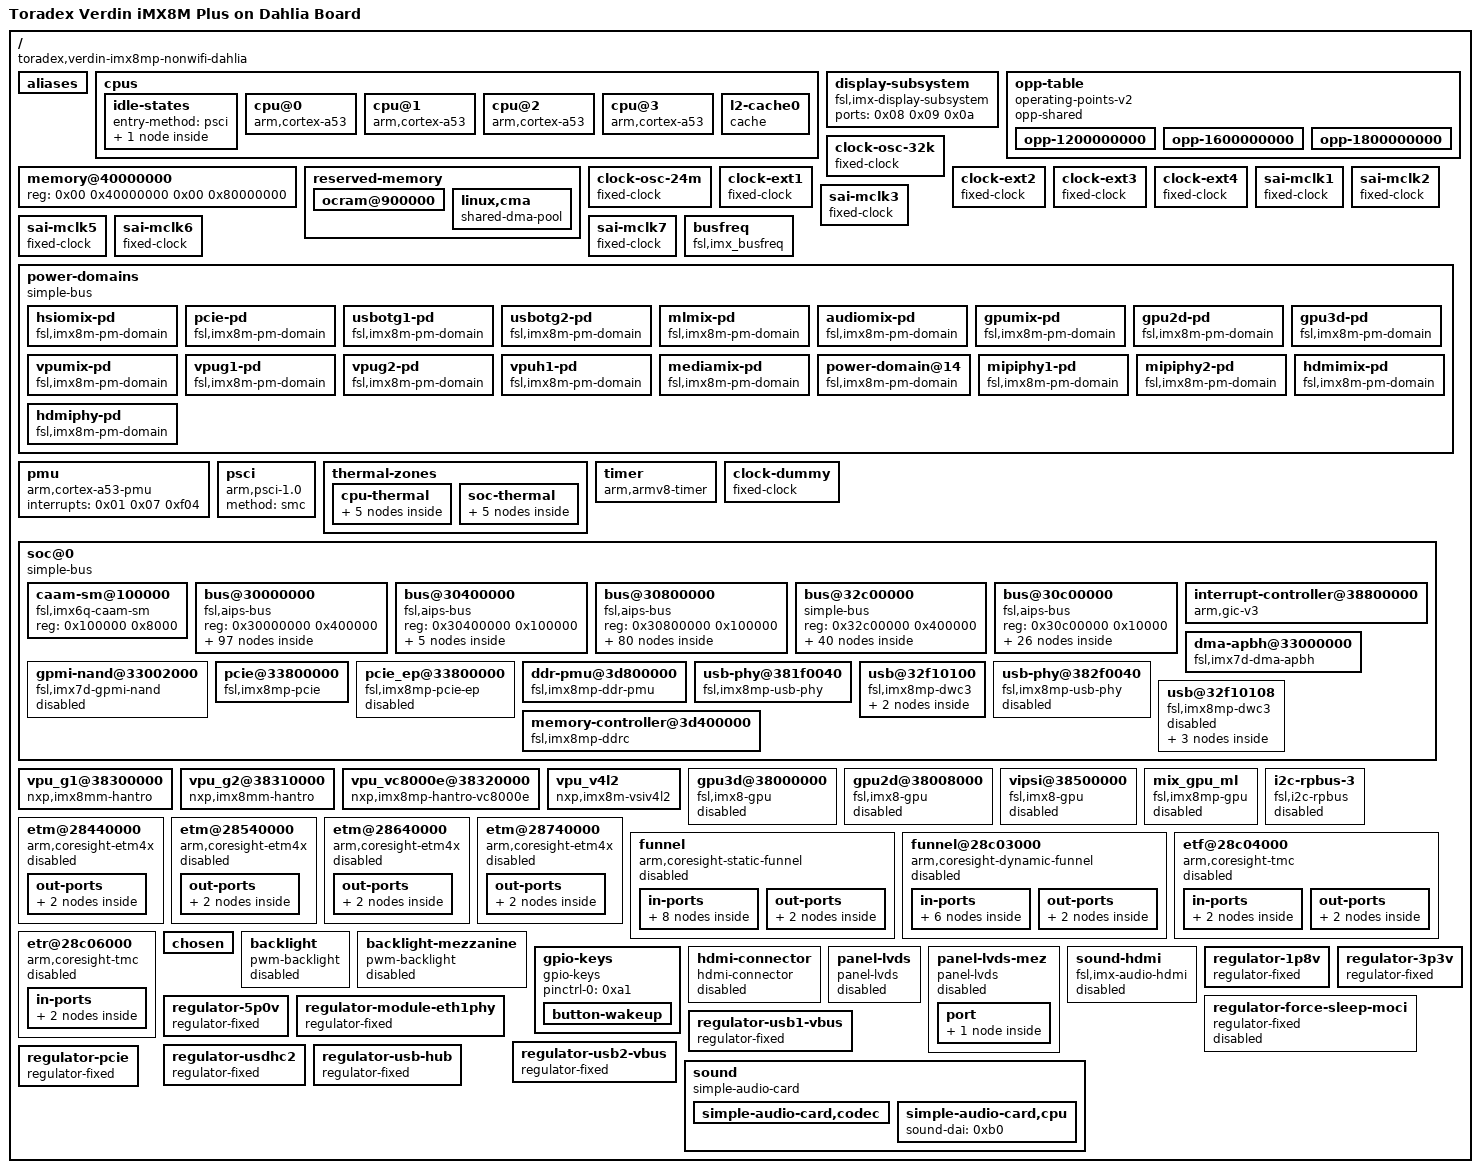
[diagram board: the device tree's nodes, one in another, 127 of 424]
/dts-v1/;

/ {
	interrupt-parent = <0x01>;
	#address-cells = <0x02>;
	#size-cells = <0x02>;
	model = "Toradex Verdin iMX8M Plus on Dahlia Board";
	compatible = "toradex,verdin-imx8mp-nonwifi-dahlia", "toradex,verdin-imx8mp-nonwifi", "toradex,verdin-imx8mp", "fsl,imx8mp";

	aliases {
		ethernet0 = "/soc@0/bus@30800000/ethernet@30bf0000";
		ethernet1 = "/soc@0/bus@30800000/ethernet@30be0000";
		gpio0 = "/soc@0/bus@30000000/gpio@30200000";
		gpio1 = "/soc@0/bus@30000000/gpio@30210000";
		gpio2 = "/soc@0/bus@30000000/gpio@30220000";
		gpio3 = "/soc@0/bus@30000000/gpio@30230000";
		gpio4 = "/soc@0/bus@30000000/gpio@30240000";			/* This is actually called "GPIO5 base address: 3024_0000h" in the TRM! WTF?? -josh */
		i2c0 = "/soc@0/bus@30800000/i2c@30a20000";
		i2c1 = "/soc@0/bus@30800000/i2c@30a30000";
		i2c2 = "/soc@0/bus@30800000/i2c@30a40000";
		i2c3 = "/soc@0/bus@30800000/i2c@30a50000";
		i2c4 = "/soc@0/bus@30800000/i2c@30ad0000";
		i2c5 = "/soc@0/bus@30800000/i2c@30ae0000";
		mmc0 = "/soc@0/bus@30800000/mmc@30b40000";
		mmc1 = "/soc@0/bus@30800000/mmc@30b50000";
		mmc2 = "/soc@0/bus@30800000/mmc@30b60000";
		serial0 = "/soc@0/bus@30800000/serial@30860000";
		serial1 = "/soc@0/bus@30800000/serial@30890000";
		serial2 = "/soc@0/bus@30800000/serial@30880000";
		serial3 = "/soc@0/bus@30800000/serial@30a60000";
		spi0 = "/soc@0/bus@30800000/spi@30bb0000";
		isi0 = "/soc@0/bus@32c00000/camera/isi@32e00000";
		isi1 = "/soc@0/bus@32c00000/camera/isi@32e02000";
		csi0 = "/soc@0/bus@32c00000/camera/csi@32e40000";
		csi1 = "/soc@0/bus@32c00000/camera/csi@32e50000";
		isp0 = "/soc@0/bus@32c00000/camera/isp@32e10000";
		isp1 = "/soc@0/bus@32c00000/camera/isp@32e20000";
		rtc0 = "/soc@0/bus@30800000/i2c@30a20000/rtc@32";
		rtc1 = "/soc@0/bus@30000000/snvs@30370000/snvs-rtc-lp";
	};

	cpus {
		#address-cells = <0x01>;
		#size-cells = <0x00>;

		idle-states {
			entry-method = "psci";

			cpu-pd-wait {
				compatible = "arm,idle-state";
				arm,psci-suspend-param = <0x10033>;
				local-timer-stop;
				entry-latency-us = <0x3e8>;
				exit-latency-us = <0x2bc>;
				min-residency-us = <0xa8c>;
				wakeup-latency-us = <0x5dc>;
				phandle = <0x06>;
			};
		};

		cpu@0 {
			device_type = "cpu";
			compatible = "arm,cortex-a53";
			reg = <0x00>;
			clock-latency = <0xee6c>;
			clocks = <0x02 0x11f>;
			operating-points-v2 = <0x03>;
			nvmem-cells = <0x04>;
			nvmem-cell-names = "speed_grade";
			enable-method = "psci";
			next-level-cache = <0x05>;
			#cooling-cells = <0x02>;
			cpu-idle-states = <0x06>;
			cpu-supply = <0x07>;
			phandle = <0x12>;
		};

		cpu@1 {
			device_type = "cpu";
			compatible = "arm,cortex-a53";
			reg = <0x01>;
			clock-latency = <0xee6c>;
			clocks = <0x02 0x11f>;
			operating-points-v2 = <0x03>;
			enable-method = "psci";
			next-level-cache = <0x05>;
			#cooling-cells = <0x02>;
			cpu-idle-states = <0x06>;
			cpu-supply = <0x07>;
			phandle = <0x13>;
		};

		cpu@2 {
			device_type = "cpu";
			compatible = "arm,cortex-a53";
			reg = <0x02>;
			clock-latency = <0xee6c>;
			clocks = <0x02 0x11f>;
			operating-points-v2 = <0x03>;
			enable-method = "psci";
			next-level-cache = <0x05>;
			#cooling-cells = <0x02>;
			cpu-idle-states = <0x06>;
			cpu-supply = <0x07>;
			phandle = <0x14>;
		};

		cpu@3 {
			device_type = "cpu";
			compatible = "arm,cortex-a53";
			reg = <0x03>;
			clock-latency = <0xee6c>;
			clocks = <0x02 0x11f>;
			operating-points-v2 = <0x03>;
			enable-method = "psci";
			next-level-cache = <0x05>;
			#cooling-cells = <0x02>;
			cpu-idle-states = <0x06>;
			cpu-supply = <0x07>;
			phandle = <0x15>;
		};

		l2-cache0 {
			compatible = "cache";
			phandle = <0x05>;
		};
	};

	display-subsystem {
		compatible = "fsl,imx-display-subsystem";
		ports = <0x08 0x09 0x0a>;
	};

	opp-table {
		compatible = "operating-points-v2";
		opp-shared;
		phandle = <0x03>;

		opp-1200000000 {
			opp-hz = <0x00 0x47868c00>;
			opp-microvolt = <0xcf850>;
			opp-supported-hw = <0x8a0 0x07>;
			clock-latency-ns = <0x249f0>;
			opp-suspend;
		};

		opp-1600000000 {
			opp-hz = <0x00 0x5f5e1000>;
			opp-microvolt = <0xe7ef0>;
			opp-supported-hw = <0xa0 0x07>;
			clock-latency-ns = <0x249f0>;
			opp-suspend;
		};

		opp-1800000000 {
			opp-hz = <0x00 0x6b49d200>;
			opp-microvolt = <0xf4240>;
			opp-supported-hw = <0x20 0x03>;
			clock-latency-ns = <0x249f0>;
			opp-suspend;
		};
	};

	memory@40000000 {
		device_type = "memory";
		reg = <0x00 0x40000000 0x00 0x80000000>;
	};

	reserved-memory {
		#address-cells = <0x02>;
		#size-cells = <0x02>;
		ranges;
		phandle = <0xb1>;

		ocram@900000 {
			no-map;
			reg = <0x00 0x900000 0x00 0x70000>;
			phandle = <0xb2>;
		};

		linux,cma {
			compatible = "shared-dma-pool";
			reusable;
			size = <0x00 0x20000000>;
			alloc-ranges = <0x00 0x40000000 0x00 0x80000000>;
			linux,cma-default;
		};
	};

	clock-osc-32k {
		compatible = "fixed-clock";
		#clock-cells = <0x00>;
		clock-frequency = <0x8000>;
		clock-output-names = "osc_32k";
		phandle = <0x23>;
	};

	clock-osc-24m {
		compatible = "fixed-clock";
		#clock-cells = <0x00>;
		clock-frequency = <0x16e3600>;
		clock-output-names = "osc_24m";
		phandle = <0x24>;
	};

	clock-ext1 {
		compatible = "fixed-clock";
		#clock-cells = <0x00>;
		clock-frequency = <0x7ed6b40>;
		clock-output-names = "clk_ext1";
		phandle = <0x25>;
	};

	clock-ext2 {
		compatible = "fixed-clock";
		#clock-cells = <0x00>;
		clock-frequency = <0x7ed6b40>;
		clock-output-names = "clk_ext2";
		phandle = <0x26>;
	};

	clock-ext3 {
		compatible = "fixed-clock";
		#clock-cells = <0x00>;
		clock-frequency = <0x7ed6b40>;
		clock-output-names = "clk_ext3";
		phandle = <0x27>;
	};

	clock-ext4 {
		compatible = "fixed-clock";
		#clock-cells = <0x00>;
		clock-frequency = <0x7ed6b40>;
		clock-output-names = "clk_ext4";
		phandle = <0x28>;
	};

	sai-mclk1 {
		compatible = "fixed-clock";
		#clock-cells = <0x00>;
		clock-frequency = <0x00>;
		clock-output-names = "sai1_mclk";
		phandle = <0xb3>;
	};

	sai-mclk2 {
		compatible = "fixed-clock";
		#clock-cells = <0x00>;
		clock-frequency = <0x00>;
		clock-output-names = "sai2_mclk";
		phandle = <0xb4>;
	};

	sai-mclk3 {
		compatible = "fixed-clock";
		#clock-cells = <0x00>;
		clock-frequency = <0x00>;
		clock-output-names = "sai3_mclk";
		phandle = <0xb5>;
	};

	sai-mclk5 {
		compatible = "fixed-clock";
		#clock-cells = <0x00>;
		clock-frequency = <0x00>;
		clock-output-names = "sai5_mclk";
		phandle = <0xb6>;
	};

	sai-mclk6 {
		compatible = "fixed-clock";
		#clock-cells = <0x00>;
		clock-frequency = <0x00>;
		clock-output-names = "sai6_mclk";
		phandle = <0xb7>;
	};

	sai-mclk7 {
		compatible = "fixed-clock";
		#clock-cells = <0x00>;
		clock-frequency = <0x00>;
		clock-output-names = "sai7_mclk";
		phandle = <0xb8>;
	};

	busfreq {
		compatible = "fsl,imx_busfreq";
		clocks = <0x02 0x29 0x02 0x70 0x02 0x71 0x02 0x71 0x02 0x11e 0x02 0x11d 0x02 0x30 0x02 0x32 0x02 0x3f 0x02 0x67 0x02 0x6b 0x02 0x5d 0x02 0x02 0x02 0x38 0x02 0x15>;
		clock-names = "dram_pll", "dram_alt_src", "dram_apb_src", "dram_apb_pre_div", "dram_core", "dram_alt_root", "sys_pll1_40m", "sys_pll1_100m", "sys_pll2_333m", "noc_div", "ahb_div", "main_axi_src", "osc_24m", "sys_pll1_800m", "dram_pll_div";
	};

	power-domains {
		compatible = "simple-bus";

		hsiomix-pd {
			compatible = "fsl,imx8m-pm-domain";
			active-wakeup;
			rpm-always-on;
			#power-domain-cells = <0x00>;
			domain-index = <0x00>;
			domain-name = "hsiomix";
			phandle = <0x0b>;
		};

		pcie-pd {
			compatible = "fsl,imx8m-pm-domain";
			#power-domain-cells = <0x00>;
			domain-index = <0x01>;
			domain-name = "pcie";
			parent-domains = <0x0b>;
			phandle = <0x78>;
		};

		usbotg1-pd {
			compatible = "fsl,imx8m-pm-domain";
			#power-domain-cells = <0x00>;
			domain-index = <0x02>;
			domain-name = "usb_otg1";
			parent-domains = <0x0b>;
			phandle = <0xb9>;
		};

		usbotg2-pd {
			compatible = "fsl,imx8m-pm-domain";
			#power-domain-cells = <0x00>;
			domain-index = <0x03>;
			domain-name = "usb_otg2";
			parent-domains = <0x0b>;
			phandle = <0xba>;
		};

		mlmix-pd {
			compatible = "fsl,imx8m-pm-domain";
			#power-domain-cells = <0x00>;
			domain-index = <0x04>;
			domain-name = "mlmix";
			clocks = <0x02 0x69 0x02 0x6a 0x02 0x10b>;
			phandle = <0x8c>;
		};

		audiomix-pd {
			compatible = "fsl,imx8m-pm-domain";
			#power-domain-cells = <0x00>;
			domain-index = <0x05>;
			domain-name = "audiomix";
			clocks = <0x02 0x13b 0x02 0x13c>;
			phandle = <0x70>;
		};

		gpumix-pd {
			compatible = "fsl,imx8m-pm-domain";
			#power-domain-cells = <0x00>;
			domain-index = <0x06>;
			domain-name = "gpumix";
			clocks = <0x02 0x107 0x02 0x66 0x02 0x65>;
			phandle = <0x0c>;
		};

		gpu2d-pd {
			compatible = "fsl,imx8m-pm-domain";
			#power-domain-cells = <0x00>;
			domain-index = <0x07>;
			domain-name = "gpu2d";
			parent-domains = <0x0c>;
			clocks = <0x02 0xf7>;
			phandle = <0x8b>;
		};

		gpu3d-pd {
			compatible = "fsl,imx8m-pm-domain";
			#power-domain-cells = <0x00>;
			domain-index = <0x08>;
			domain-name = "gpu3d";
			parent-domains = <0x0c>;
			clocks = <0x02 0xf8 0x02 0x134>;
			phandle = <0x8a>;
		};

		vpumix-pd {
			compatible = "fsl,imx8m-pm-domain";
			#power-domain-cells = <0x00>;
			domain-index = <0x09>;
			domain-name = "vpumix";
			clocks = <0x02 0x11a>;
			phandle = <0x0d>;
		};

		vpug1-pd {
			compatible = "fsl,imx8m-pm-domain";
			#power-domain-cells = <0x00>;
			domain-index = <0x0a>;
			domain-name = "vpu_g1";
			parent-domains = <0x0d>;
			clocks = <0x02 0x106>;
			phandle = <0x87>;
		};

		vpug2-pd {
			compatible = "fsl,imx8m-pm-domain";
			#power-domain-cells = <0x00>;
			domain-index = <0x0b>;
			domain-name = "vpu_g2";
			parent-domains = <0x0d>;
			clocks = <0x02 0x10a>;
			phandle = <0x88>;
		};

		vpuh1-pd {
			compatible = "fsl,imx8m-pm-domain";
			#power-domain-cells = <0x00>;
			domain-index = <0x0c>;
			domain-name = "vpu_h1";
			parent-domains = <0x0d>;
			clocks = <0x02 0x109>;
			phandle = <0x89>;
		};

		mediamix-pd {
			compatible = "fsl,imx8m-pm-domain";
			#power-domain-cells = <0x00>;
			domain-index = <0x0d>;
			domain-name = "mediamix";
			clocks = <0x02 0x10e 0x02 0x10d>;
			phandle = <0x0e>;
		};

		power-domain@14 {
			compatible = "fsl,imx8m-pm-domain";
			#power-domain-cells = <0x00>;
			domain-index = <0x0e>;
			domain-name = "ispdwp";
			parent-domains = <0x0e>;
			phandle = <0x6b>;
		};

		mipiphy1-pd {
			compatible = "fsl,imx8m-pm-domain";
			#power-domain-cells = <0x00>;
			domain-index = <0x0f>;
			domain-name = "mipi_phy1";
			parent-domains = <0x0e>;
			phandle = <0x60>;
		};

		mipiphy2-pd {
			compatible = "fsl,imx8m-pm-domain";
			#power-domain-cells = <0x00>;
			domain-index = <0x10>;
			domain-name = "mipi_phy2";
			parent-domains = <0x0e>;
			phandle = <0x6e>;
		};

		hdmimix-pd {
			compatible = "fsl,imx8m-pm-domain";
			#power-domain-cells = <0x00>;
			domain-index = <0x11>;
			domain-name = "hdmimix";
			clocks = <0x02 0x116 0x02 0x63 0x02 0xa8>;
			phandle = <0x0f>;
		};

		hdmiphy-pd {
			compatible = "fsl,imx8m-pm-domain";
			#power-domain-cells = <0x00>;
			domain-index = <0x12>;
			domain-name = "hdmi_phy";
			parent-domains = <0x0f>;
			phandle = <0x75>;
		};
	};

	pmu {
		compatible = "arm,cortex-a53-pmu";
		interrupts = <0x01 0x07 0xf04>;
	};

	psci {
		compatible = "arm,psci-1.0";
		method = "smc";
	};

	thermal-zones {

		cpu-thermal {
			polling-delay-passive = <0xfa>;
			polling-delay = <0x7d0>;
			thermal-sensors = <0x10 0x00>;

			trips {

				trip0 {
					temperature = <0x17318>;
					hysteresis = <0x7d0>;
					type = "passive";
					phandle = <0x11>;
				};

				trip1 {
					temperature = <0x19a28>;
					hysteresis = <0x7d0>;
					type = "critical";
					phandle = <0xbb>;
				};
			};

			cooling-maps {

				map0 {
					trip = <0x11>;
					cooling-device = <0x12 0xffffffff 0xffffffff 0x13 0xffffffff 0xffffffff 0x14 0xffffffff 0xffffffff 0x15 0xffffffff 0xffffffff>;
				};
			};
		};

		soc-thermal {
			polling-delay-passive = <0xfa>;
			polling-delay = <0x7d0>;
			thermal-sensors = <0x10 0x01>;

			trips {

				trip0 {
					temperature = <0x14c08>;
					hysteresis = <0x7d0>;
					type = "passive";
					phandle = <0x16>;
				};

				trip1 {
					temperature = <0x17318>;
					hysteresis = <0x7d0>;
					type = "critical";
					phandle = <0xbc>;
				};
			};

			cooling-maps {

				map0 {
					trip = <0x16>;
					cooling-device = <0x12 0xffffffff 0xffffffff 0x13 0xffffffff 0xffffffff 0x14 0xffffffff 0xffffffff 0x15 0xffffffff 0xffffffff>;
				};
			};
		};
	};

	timer {
		compatible = "arm,armv8-timer";
		interrupts = <0x01 0x0d 0xf08 0x01 0x0e 0xf08 0x01 0x0b 0xf08 0x01 0x0a 0xf08>;
		clock-frequency = <0x7a1200>;
		arm,no-tick-in-suspend;
		interrupt-parent = <0x01>;
	};

	clock-dummy {
		compatible = "fixed-clock";
		#clock-cells = <0x00>;
		clock-frequency = <0x00>;
		clock-output-names = "clk_dummy";
		phandle = <0xbd>;
	};

	soc@0 {
		compatible = "simple-bus";
		#address-cells = <0x01>;
		#size-cells = <0x01>;
		ranges = <0x00 0x00 0x00 0x3e000000>;
		nvmem-cells = <0x17>;
		nvmem-cell-names = "soc_unique_id";

		caam-sm@100000 {
			compatible = "fsl,imx6q-caam-sm";
			reg = <0x100000 0x8000>;
			phandle = <0xbe>;
		};

		bus@30000000 {
			compatible = "fsl,aips-bus", "simple-bus";
			reg = <0x30000000 0x400000>;
			#address-cells = <0x01>;
			#size-cells = <0x01>;
			ranges;
			phandle = <0xbf>;

			gpio@30200000 {
				compatible = "fsl,imx8mp-gpio", "fsl,imx35-gpio";
				reg = <0x30200000 0x10000>;
				interrupts = <0x00 0x40 0x04 0x00 0x41 0x04>;
				clocks = <0x02 0xc1>;
				gpio-controller;
				#gpio-cells = <0x02>;
				interrupt-controller;
				#interrupt-cells = <0x02>;
				gpio-ranges = <0x18 0x00 0x05 0x1e>;
				gpio-line-names = "SODIMM_206", "SODIMM_208", "", "", "", "SODIMM_210", "SODIMM_212", "SODIMM_216", "SODIMM_218", "", "", "SODIMM_16", "SODIMM_155", "SODIMM_157", "SODIMM_185", "SODIMM_91";
				phandle = <0x2d>;
			};

			gpio@30210000 {
				compatible = "fsl,imx8mp-gpio", "fsl,imx35-gpio";
				reg = <0x30210000 0x10000>;
				interrupts = <0x00 0x42 0x04 0x00 0x43 0x04>;
				clocks = <0x02 0xc2>;
				gpio-controller;
				#gpio-cells = <0x02>;
				interrupt-controller;
				#interrupt-cells = <0x02>;
				gpio-ranges = <0x18 0x00 0x23 0x15>;
				gpio-line-names = "", "", "", "", "", "", "SODIMM_143", "SODIMM_141", "", "", "SODIMM_161", "", "SODIMM_84", "SODIMM_78", "SODIMM_74", "SODIMM_80", "SODIMM_82", "SODIMM_70", "SODIMM_72";
				phandle = <0x49>;
			};

			gpio@30220000 {
				compatible = "fsl,imx8mp-gpio", "fsl,imx35-gpio";
				reg = <0x30220000 0x10000>;
				interrupts = <0x00 0x44 0x04 0x00 0x45 0x04>;
				clocks = <0x02 0xc3>;
				gpio-controller;
				#gpio-cells = <0x02>;
				interrupt-controller;
				#interrupt-cells = <0x02>;
				gpio-ranges = <0x18 0x00 0x38 0x1a 0x18 0x1a 0x90 0x04>;
				gpio-line-names = "SODIMM_52", "SODIMM_54", "", "", "", "", "SODIMM_56", "SODIMM_58", "SODIMM_60", "SODIMM_62", "", "", "", "", "SODIMM_66", "", "SODIMM_64", "", "", "SODIMM_34", "SODIMM_19", "", "SODIMM_32", "", "", "SODIMM_30", "SODIMM_59", "SODIMM_57", "SODIMM_63", "SODIMM_61";
				phandle = <0xa3>;
			};

			gpio@30230000 {
				compatible = "fsl,imx8mp-gpio", "fsl,imx35-gpio";
				reg = <0x30230000 0x10000>;
				interrupts = <0x00 0x46 0x04 0x00 0x47 0x04>;
				clocks = <0x02 0xc4>;
				gpio-controller;
				#gpio-cells = <0x02>;
				interrupt-controller;
				#interrupt-cells = <0x02>;
				gpio-ranges = <0x18 0x00 0x52 0x20>;
				gpio-line-names = "SODIMM_252", "SODIMM_222", "SODIMM_36", "SODIMM_220", "SODIMM_193", "SODIMM_191", "SODIMM_201", "SODIMM_203", "SODIMM_205", "SODIMM_207", "SODIMM_199", "SODIMM_197", "SODIMM_221", "SODIMM_219", "SODIMM_217", "SODIMM_215", "SODIMM_211", "SODIMM_213", "SODIMM_189", "SODIMM_244", "SODIMM_38", "", "SODIMM_76", "SODIMM_135", "SODIMM_133", "SODIMM_17", "SODIMM_24", "SODIMM_26", "SODIMM_21", "SODIMM_256", "SODIMM_48", "SODIMM_44";
				pinctrl-names = "default";
				pinctrl-0 = <0x19>;
				phandle = <0x41>;
			};

			gpio@30240000 {
				compatible = "fsl,imx8mp-gpio", "fsl,imx35-gpio";
				reg = <0x30240000 0x10000>;
				interrupts = <0x00 0x48 0x04 0x00 0x49 0x04>;
				clocks = <0x02 0xc5>;
				gpio-controller;
				#gpio-cells = <0x02>;
				interrupt-controller;
				#interrupt-cells = <0x02>;
				gpio-ranges = <0x18 0x00 0x72 0x1e>;
				gpio-line-names = "SODIMM_42", "SODIMM_46", "SODIMM_187", "SODIMM_20", "SODIMM_22", "SODIMM_15", "SODIMM_196", "SODIMM_200", "SODIMM_198", "SODIMM_202", "SODIMM_164", "SODIMM_152", "SODIMM_116", "SODIMM_128", "", "", "SODIMM_55", "SODIMM_53", "SODIMM_95", "SODIMM_93", "SODIMM_14", "SODIMM_12", "SODIMM_129", "SODIMM_131", "SODIMM_137", "SODIMM_139", "SODIMM_147", "SODIMM_149", "SODIMM_151", "SODIMM_153";
				phandle = <0x37>;
			};

			tmu@30260000 {
				compatible = "fsl,imx8mp-tmu";
				reg = <0x30260000 0x10000>;
				clocks = <0x02 0x119>;
				#thermal-sensor-cells = <0x01>;
				phandle = <0x10>;
			};

			watchdog@30280000 {
				compatible = "fsl,imx8mp-wdt", "fsl,imx21-wdt";
				reg = <0x30280000 0x10000>;
				interrupts = <0x00 0x4e 0x04>;
				clocks = <0x02 0x103>;
				status = "okay";
				fsl,ext-reset-output;
				pinctrl-names = "default";
				pinctrl-0 = <0x1a>;
				phandle = <0xc0>;
			};

			watchdog@30290000 {
				compatible = "fsl,imx8mp-wdt", "fsl,imx21-wdt";
				reg = <0x30290000 0x10000>;
				interrupts = <0x00 0x4f 0x04>;
				clocks = <0x02 0x104>;
				status = "disabled";
				phandle = <0xc1>;
			};

			watchdog@302a0000 {
				compatible = "fsl,imx8mp-wdt", "fsl,imx21-wdt";
				reg = <0x302a0000 0x10000>;
				interrupts = <0x00 0x0a 0x04>;
				clocks = <0x02 0x105>;
				status = "disabled";
				phandle = <0xc2>;
			};

			pinctrl@30330000 {
				compatible = "fsl,imx8mp-iomuxc";
				reg = <0x30330000 0x10000>;
				pinctrl-names = "default";
				pinctrl-0 = <0x1b 0x1c 0x1d 0x1e 0x1f 0x20 0x21>;
				phandle = <0x18>;

				btuartgrp {
					fsl,pins = <0x1f8 0x458 0x00 0x01 0x00 0x1c4 0x1f4 0x454 0x00 0x01 0x00 0x1c4 0x1f0 0x450 0x600 0x01 0x06 0x1c4 0x1fc 0x45c 0x5fc 0x01 0x03 0x1c4>;
					phandle = <0xc3>;
				};

				ctrlsleepmocigrp {
					fsl,pins = <0x1bc 0x41c 0x00 0x05 0x00 0x1c4>;
					phandle = <0x19>;
				};

				/* 
					muxreg    1e8 = SW_MUX_CTL_PAD_ECSPI1_MISO SW MUX
					conf_reg  448 = SW_PAD_CTL_PAD_ECSPI1_MISO SW PAD Control
					input_reg 55c = 
					mux_val    00 = 000 ALT0_ECSPI1_MISO
					input_val  00 = Selecting Pad: ECSPI1_MOSI for Mode: ALT0
					pad_set   1c4 = 1=1 PE_1_PULL_ENABLE 1=HYS_1_SCHMITT 1=PUE_1_WEAK_PULL_UP 0=0 ODE_0_OPEN_DRAIN_DISABLE 0=FSEL_0_SLOW_SLEW_RATE 0=RES 10=2X drive 0=RES
				*/


				/* Note that I think the last two pins on this group are from somewhere else and do not match the CS pins defined in the ECSPI node below? */

				ecspi1grp {
					fsl,pins = <0x1e8 0x448 0x55c 0x00 0x00 0x1c4 0x1e4 0x444 0x560 0x00 0x00 0x04 0x1e0 0x440 0x558 0x00 0x00 0x04 0x2c 0x28c 0x00 0x00 0x00 0x184 0x18 0x278 0x00 0x00 0x00 0x1c4>;
					phandle = <0x2e>;
				};

				/* /dev/spidev1.3 using GIPO on the multi_spi_cs line. -josh 4/25/2025 */
				/* The name of this pad is * MX8MP_IOMUXC_ECSPI1_SS0__GPIO5_IO09 , we got the values form the dts-arm64/imx8mp-pinfunc.h header file */
				/* Format: <mux_reg conf_reg input_reg mux_mode input_val> */
				/* To make this be pull-up, open collector then check out IOMUXC_SW_PAD_CTL_PAD_ECSPI1_SS0 */ 

				/* 
					muxreg    1ec = IOMUXC_SW_MUX_CTL_PAD_ECSPI1_SS0)
					conf_reg  44c = SW_PAD_CTL_PAD_ECSPI1_SS0 SW PAD
					input_reg 564 = (This would have to be set right too for CS monitoring) 
					mux_val    05 = ALT5_GPIO5_IO[9] — Select mux mode: ALT5 mux port: GPIO5_IO09 of instance: gpio5. Note that the SION field is in bit 4!
					input_val  00 = 0 SELECT_ECSPI1_SS0_ALT0 — Selecting Pad: ECSPI1_SS0 for Mode: ALT0
					pad_set   1c4 = 1=1 PE_1_PULL_ENABLE 1=HYS_1_SCHMITT 1=PUE_1_WEAK_PULL_UP 0=0 ODE_0_OPEN_DRAIN_DISABLE 0=FSEL_0_SLOW_SLEW_RATE 0=RES 10=2X drive 0=RES
				*/

				pinctrl_ecspi1_cs3:pinctrl_ecspi1_cs3 {
					fsl,pins =  < 0x1EC 0x44C 0x564 0x5 0x00 0x1c4 >;
				};

				eqosgrp {
					fsl,pins = <0x54 0x2b4 0x00 0x00 0x00 0x03 0x58 0x2b8 0x590 0x00 0x01 0x03 0x7c 0x2dc 0x00 0x00 0x00 0x91 0x80 0x2e0 0x00 0x00 0x00 0x91 0x84 0x2e4 0x00 0x00 0x00 0x91 0x88 0x2e8 0x00 0x00 0x00 0x91 0x78 0x2d8 0x00 0x00 0x00 0x91 0x74 0x2d4 0x00 0x00 0x00 0x91 0x68 0x2c8 0x00 0x00 0x00 0x1f 0x64 0x2c4 0x00 0x00 0x00 0x1f 0x60 0x2c0 0x00 0x00 0x00 0x1f 0x5c 0x2bc 0x00 0x00 0x00 0x1f 0x6c 0x2cc 0x00 0x00 0x00 0x1f 0x70 0x2d0 0x00 0x00 0x00 0x1f>;
					phandle = <0x5c>;
				};

				ethtpmintgrp {
					fsl,pins = <0x3c 0x29c 0x00 0x00 0x00 0x1c4>;
					phandle = <0xc4>;
				};

				fecgrp {
					fsl,pins = <0x158 0x3b8 0x00 0x04 0x00 0x03 0x15c 0x3bc 0x57c 0x04 0x01 0x03 0x160 0x3c0 0x580 0x04 0x01 0x91 0x164 0x3c4 0x584 0x04 0x01 0x91 0x168 0x3c8 0x00 0x04 0x00 0x91 0x16c 0x3cc 0x00 0x04 0x00 0x91 0x174 0x3d4 0x00 0x04 0x00 0x91 0x170 0x3d0 0x588 0x04 0x01 0x91 0x178 0x3d8 0x00 0x04 0x00 0x1f 0x17c 0x3dc 0x00 0x04 0x00 0x1f 0x180 0x3e0 0x00 0x04 0x00 0x1f 0x184 0x3e4 0x00 0x04 0x00 0x1f 0x188 0x3e8 0x00 0x04 0x00 0x1f 0x18c 0x3ec 0x00 0x04 0x00 0x1f 0x190 0x3f0 0x00 0x05 0x00 0x1c4>;
					phandle = <0x57>;
				};

				fecsleepgrp {
					fsl,pins = <0x158 0x3b8 0x00 0x04 0x00 0x03 0x15c 0x3bc 0x57c 0x04 0x01 0x03 0x160 0x3c0 0x580 0x04 0x01 0x91 0x164 0x3c4 0x584 0x04 0x01 0x91 0x168 0x3c8 0x00 0x04 0x00 0x91 0x16c 0x3cc 0x00 0x04 0x00 0x91 0x174 0x3d4 0x00 0x04 0x00 0x91 0x170 0x3d0 0x588 0x04 0x01 0x91 0x178 0x3d8 0x00 0x05 0x00 0x1f 0x17c 0x3dc 0x00 0x05 0x00 0x1f 0x180 0x3e0 0x00 0x05 0x00 0x1f 0x184 0x3e4 0x00 0x05 0x00 0x1f 0x188 0x3e8 0x00 0x05 0x00 0x1f 0x18c 0x3ec 0x00 0x05 0x00 0x1f 0x190 0x3f0 0x00 0x05 0x00 0x184>;
					phandle = <0x58>;
				};

				flexcan1grp {
					fsl,pins = <0x1d8 0x438 0x54c 0x04 0x02 0x154 0x1d4 0x434 0x00 0x04 0x00 0x154>;
					phandle = <0x33>;
				};

				flexcan2grp {
					fsl,pins = <0x1b4 0x414 0x550 0x03 0x01 0x154 0x1b0 0x410 0x00 0x03 0x00 0x154>;
					phandle = <0x34>;
				};

				flexspi0grp {
					fsl,pins = <0xe0 0x340 0x00 0x01 0x00 0x1c2 0xe4 0x344 0x00 0x01 0x00 0x82 0x118 0x378 0x00 0x01 0x00 0x82 0xf8 0x358 0x00 0x01 0x00 0x82 0xfc 0x35c 0x00 0x01 0x00 0x82 0x100 0x360 0x00 0x01 0x00 0x82 0x104 0x364 0x00 0x01 0x00 0x82 0x120 0x380 0x00 0x05 0x00 0x82>;
					phandle = <0x54>;
				};

				gpio1grp {
					fsl,pins = <0x14 0x274 0x00 0x00 0x00 0x184>;
					phandle = <0x1b>;
				};

				gpio2grp {
					fsl,pins = <0x18 0x278 0x00 0x00 0x00 0x1c4>;
					phandle = <0xc5>;
				};

				gpio3grp {
					fsl,pins = <0x28 0x288 0x00 0x00 0x00 0x184>;
					phandle = <0x1c>;
				};

				gpio4grp {
					fsl,pins = <0x2c 0x28c 0x00 0x00 0x00 0x184>;
					phandle = <0xc6>;
				};

				gpio5grp {
					fsl,pins = <0x30 0x290 0x00 0x00 0x00 0x184>;
					phandle = <0xc7>;
				};

				gpio6grp {
					fsl,pins = <0x34 0x294 0x00 0x00 0x00 0x184>;
					phandle = <0xc8>;
				};

				gpio7grp {
					fsl,pins = <0x154 0x3b4 0x00 0x05 0x00 0x184>;
					phandle = <0x1d>;
				};

				gpio8grp {
					fsl,pins = <0x14c 0x3ac 0x00 0x05 0x00 0x184>;
					phandle = <0x1e>;
				};

				gpio9dsigrp {
					fsl,pins = <0x1ac 0x40c 0x00 0x05 0x00 0x1c4>;
					phandle = <0x43>;
				};

				gpio10dsigrp {
					fsl,pins = <0x1b8 0x418 0x00 0x05 0x00 0x1c4>;
					phandle = <0x42>;
				};

				gpiohog1grp {
					fsl,pins = <0x1f8 0x458 0x00 0x05 0x00 0x1c4 0x1f4 0x454 0x00 0x05 0x00 0x1c4 0x1f0 0x450 0x00 0x05 0x00 0x1c4 0x1fc 0x45c 0x00 0x05 0x00 0x1c4>;
					phandle = <0x1f>;
				};

				gpiohog2grp {
					fsl,pins = <0x1d0 0x430 0x00 0x05 0x00 0x1c4>;
					phandle = <0x20>;
				};

				gpiohog3grp {
					fsl,pins = <0x50 0x2b0 0x00 0x00 0x00 0x1c4>;
					phandle = <0x21>;
				};

				gpiohog4grp {
					fsl,pins = <0x238 0x498 0x00 0x05 0x00 0x1c4 0x23c 0x49c 0x00 0x05 0x00 0x1c4>;
					phandle = <0xc9>;
				};

				gpiokeysgrp {
					fsl,pins = <0x148 0x3a8 0x00 0x05 0x00 0x1c4>;
					phandle = <0xa1>;
				};

				hdmihoggrp {
					fsl,pins = <0x248 0x4a8 0x00 0x00 0x00 0x40000019 0x240 0x4a0 0x00 0x00 0x00 0x400001c3 0x244 0x4a4 0x00 0x00 0x00 0x400001c3 0x24c 0x4ac 0x00 0x00 0x00 0x40000019>;
					phandle = <0xca>;
				};

				i2c1grp {
					fsl,pins = <0x200 0x460 0x5a4 0x00 0x02 0x400001c6 0x204 0x464 0x5a8 0x00 0x02 0x400001c6>;
					phandle = <0x35>;
				};

				i2c1gpiogrp {
					fsl,pins = <0x200 0x460 0x00 0x05 0x00 0x400001c6 0x204 0x464 0x00 0x05 0x00 0x400001c6>;
					phandle = <0x36>;
				};

				i2c2grp {
					fsl,pins = <0x208 0x468 0x5ac 0x00 0x02 0x400001c6 0x20c 0x46c 0x5b0 0x00 0x02 0x400001c6>;
					phandle = <0x3a>;
				};

				i2c2gpiogrp {
					fsl,pins = <0x208 0x468 0x00 0x05 0x00 0x400001c6 0x20c 0x46c 0x00 0x05 0x00 0x400001c6>;
					phandle = <0x3b>;
				};

				i2c3grp {
					fsl,pins = <0x210 0x470 0x5b4 0x00 0x04 0x400001c6 0x214 0x474 0x5b8 0x00 0x04 0x400001c6>;
					phandle = <0x3c>;
				};

				i2c3gpiogrp {
					fsl,pins = <0x210 0x470 0x00 0x05 0x00 0x400001c6 0x214 0x474 0x00 0x05 0x00 0x400001c6>;
					phandle = <0x3d>;
				};

				i2c4grp {
					fsl,pins = <0x218 0x478 0x5bc 0x00 0x05 0x400001c6 0x21c 0x47c 0x5c0 0x00 0x05 0x400001c6>;
					phandle = <0x3e>;
				};

				i2c4gpiogrp {
					fsl,pins = <0x218 0x478 0x00 0x05 0x00 0x400001c6 0x21c 0x47c 0x00 0x05 0x00 0x400001c6>;
					phandle = <0x3f>;
				};

				i2s2bclktouchresetgrp {
					fsl,pins = <0x1c8 0x428 0x00 0x05 0x00 0x184>;
					phandle = <0x44>;
				};

				i2s2doutdsi1bklengrp {
					fsl,pins = <0x1cc 0x42c 0x00 0x05 0x00 0x184>;
					phandle = <0x9e>;
				};

				pciegrp {
					fsl,pins = <0x194 0x3f4 0x00 0x05 0x00 0x04 0xd8 0x338 0x00 0x05 0x00 0x1c4>;
					phandle = <0x7c>;
				};

				pmicirqgrp {
					fsl,pins = <0x20 0x280 0x00 0x00 0x00 0x1c4>;
					phandle = <0x38>;
				};

				pwm1grp {
					fsl,pins = <0x1dc 0x43c 0x00 0x01 0x00 0x06>;
					phandle = <0x29>;
				};

				pwm2grp {
					fsl,pins = <0x40 0x2a0 0x00 0x02 0x00 0x06>;
					phandle = <0x2a>;
				};

				pwm3grp {
					fsl,pins = <0x130 0x390 0x00 0x02 0x00 0x06>;
					phandle = <0x2b>;
				};

				pwm3dsi1hpdgpiogrp {
					fsl,pins = <0x130 0x390 0x00 0x05 0x00 0x184>;
					phandle = <0xa4>;
				};

				regethgrp {
					fsl,pins = <0xdc 0x33c 0x00 0x05 0x00 0x184>;
					phandle = <0xa9>;
				};

				sai1grp {
					fsl,pins = <0x198 0x3f8 0x00 0x00 0x00 0x96 0x150 0x3b0 0x00 0x00 0x00 0x1d6 0x144 0x3a4 0x4d4 0x01 0x00 0x1d6 0x138 0x398 0x4d8 0x02 0x00 0x1d6 0x12c 0x38c 0x00 0x01 0x00 0x96>;
					phandle = <0x46>;
				};

				sai3grp {
					fsl,pins = <0x1c0 0x420 0x4e4 0x00 0x01 0x1d6 0x1c8 0x428 0x4e8 0x00 0x01 0x1d6 0x1cc 0x42c 0x00 0x00 0x00 0x96 0x1c4 0x424 0x4ec 0x00 0x01 0x1d6>;
					phandle = <0xcb>;
				};

				uart1grp {
					fsl,pins = <0x1a4 0x404 0x5e4 0x04 0x02 0x1c4 0x1a8 0x408 0x00 0x04 0x00 0x1c4 0x220 0x480 0x5e8 0x00 0x04 0x1c4 0x224 0x484 0x00 0x00 0x00 0x1c4>;
					phandle = <0x2f>;
				};

				uart2grp {
					fsl,pins = <0xa4 0x304 0x5ec 0x04 0x00 0x1c4 0xa8 0x308 0x00 0x04 0x00 0x1c4 0x228 0x488 0x5f0 0x00 0x06 0x1c4 0x22c 0x48c 0x00 0x00 0x00 0x1c4>;
					phandle = <0x31>;
				};

				uart3grp {
					fsl,pins = <0x230 0x490 0x5f8 0x00 0x06 0x1c4 0x234 0x494 0x00 0x00 0x00 0x1c4>;
					phandle = <0x30>;
				};

				uart4grp {
					fsl,pins = <0x238 0x498 0x600 0x00 0x08 0x1c4 0x23c 0x49c 0x00 0x00 0x00 0x1c4>;
					phandle = <0x48>;
				};

				usb1vbusgrp {
					fsl,pins = <0x44 0x2a4 0x00 0x00 0x00 0x106>;
					phandle = <0xab>;
				};

				usb1idgrp {
					fsl,pins = <0xb4 0x314 0x00 0x05 0x00 0x1c4>;
					phandle = <0x80>;
				};

				usb1ocngrp {
					fsl,pins = <0x48 0x2a8 0x00 0x01 0x00 0x1c4>;
					phandle = <0x7e>;
				};

				usb2vbusgrp {
					fsl,pins = <0x4c 0x2ac 0x00 0x00 0x00 0x106>;
					phandle = <0xac>;
				};

				usdhc1grp {
					fsl,pins = <0x8c 0x2ec 0x00 0x00 0x00 0x190 0x90 0x2f0 0x00 0x00 0x00 0x1d0 0x94 0x2f4 0x00 0x00 0x00 0x1d0 0x98 0x2f8 0x00 0x00 0x00 0x1d0 0x9c 0x2fc 0x00 0x00 0x00 0x1d0 0xa0 0x300 0x00 0x00 0x00 0x1d0>;
					phandle = <0xcc>;
				};

				usdhc1-100mhzgrp {
					fsl,pins = <0x8c 0x2ec 0x00 0x00 0x00 0x194 0x90 0x2f0 0x00 0x00 0x00 0x1d4 0x94 0x2f4 0x00 0x00 0x00 0x1d4 0x98 0x2f8 0x00 0x00 0x00 0x1d4 0x9c 0x2fc 0x00 0x00 0x00 0x1d4 0xa0 0x300 0x00 0x00 0x00 0x1d4>;
					phandle = <0xcd>;
				};

				usdhc1-200mhzgrp {
					fsl,pins = <0x8c 0x2ec 0x00 0x00 0x00 0x196 0x90 0x2f0 0x00 0x00 0x00 0x1d6 0x94 0x2f4 0x00 0x00 0x00 0x1d6 0x98 0x2f8 0x00 0x00 0x00 0x1d6 0x9c 0x2fc 0x00 0x00 0x00 0x1d6 0xa0 0x300 0x00 0x00 0x00 0x1d6>;
					phandle = <0xce>;
				};

				usdhc2cdgrp {
					fsl,pins = <0xbc 0x31c 0x00 0x05 0x00 0x1c4>;
					phandle = <0x4b>;
				};

				usdhc2cdslpgrp {
					fsl,pins = <0xbc 0x31c 0x00 0x05 0x00 0x00>;
					phandle = <0x4f>;
				};

				usdhc2pwrengrp {
					fsl,pins = <0x1a0 0x400 0x00 0x05 0x00 0x04>;
					phandle = <0xad>;
				};

				usdhc2grp {
					fsl,pins = <0x24 0x284 0x00 0x01 0x00 0x04 0xc0 0x320 0x00 0x00 0x00 0x190 0xc4 0x324 0x00 0x00 0x00 0x1d0 0xc8 0x328 0x00 0x00 0x00 0x1d0 0xcc 0x32c 0x00 0x00 0x00 0x1d0 0xd0 0x330 0x00 0x00 0x00 0x1d0 0xd4 0x334 0x00 0x00 0x00 0x1d0>;
					phandle = <0x4a>;
				};

				usdhc2-100mhzgrp {
					fsl,pins = <0x24 0x284 0x00 0x01 0x00 0x04 0xc0 0x320 0x00 0x00 0x00 0x194 0xc4 0x324 0x00 0x00 0x00 0x1d4 0xc8 0x328 0x00 0x00 0x00 0x1d4 0xcc 0x32c 0x00 0x00 0x00 0x1d4 0xd0 0x330 0x00 0x00 0x00 0x1d4 0xd4 0x334 0x00 0x00 0x00 0x1d4>;
					phandle = <0x4c>;
				};

				usdhc2-200mhzgrp {
					fsl,pins = <0x24 0x284 0x00 0x01 0x00 0x04 0xc0 0x320 0x00 0x00 0x00 0x196 0xc4 0x324 0x00 0x00 0x00 0x1d6 0xc8 0x328 0x00 0x00 0x00 0x1d6 0xcc 0x32c 0x00 0x00 0x00 0x1d6 0xd0 0x330 0x00 0x00 0x00 0x1d6 0xd4 0x334 0x00 0x00 0x00 0x1d6>;
					phandle = <0x4d>;
				};

				usdhc2slpgrp {
					fsl,pins = <0x24 0x284 0x00 0x01 0x00 0x00 0xc0 0x320 0x00 0x00 0x00 0x100 0xc4 0x324 0x00 0x00 0x00 0x100 0xc8 0x328 0x00 0x00 0x00 0x100 0xcc 0x32c 0x00 0x00 0x00 0x100 0xd0 0x330 0x00 0x00 0x00 0x100 0xd4 0x334 0x00 0x00 0x00 0x100>;
					phandle = <0x4e>;
				};

				usdhc3grp {
					fsl,pins = <0x38 0x298 0x00 0x04 0x00 0x1d1 0xe8 0x348 0x630 0x02 0x01 0x190 0xec 0x34c 0x624 0x02 0x01 0x1d0 0xf0 0x350 0x628 0x02 0x01 0x1d0 0xf4 0x354 0x62c 0x02 0x01 0x1d0 0x108 0x368 0x610 0x02 0x01 0x1d0 0x10c 0x36c 0x614 0x02 0x01 0x1d0 0x110 0x370 0x618 0x02 0x01 0x1d0 0x114 0x374 0x61c 0x02 0x01 0x1d0 0x11c 0x37c 0x620 0x02 0x01 0x1d0 0x124 0x384 0x604 0x02 0x01 0x190 0x128 0x388 0x60c 0x02 0x01 0x1d0>;
					phandle = <0x51>;
				};

				usdhc3-100mhzgrp {
					fsl,pins = <0x38 0x298 0x00 0x04 0x00 0x1d1 0xe8 0x348 0x630 0x02 0x01 0x194 0xec 0x34c 0x624 0x02 0x01 0x1d4 0xf0 0x350 0x628 0x02 0x01 0x1d4 0xf4 0x354 0x62c 0x02 0x01 0x1d4 0x108 0x368 0x610 0x02 0x01 0x1d4 0x10c 0x36c 0x614 0x02 0x01 0x1d4 0x110 0x370 0x618 0x02 0x01 0x1d4 0x114 0x374 0x61c 0x02 0x01 0x1d4 0x11c 0x37c 0x620 0x02 0x01 0x1d4 0x124 0x384 0x604 0x02 0x01 0x194 0x128 0x388 0x60c 0x02 0x01 0x1d4>;
					phandle = <0x52>;
				};

				usdhc3-200mhzgrp {
					fsl,pins = <0x38 0x298 0x00 0x04 0x00 0x1d1 0xe8 0x348 0x630 0x02 0x01 0x196 0xec 0x34c 0x624 0x02 0x01 0x1d2 0xf0 0x350 0x628 0x02 0x01 0x1d2 0xf4 0x354 0x62c 0x02 0x01 0x1d2 0x108 0x368 0x610 0x02 0x01 0x1d2 0x10c 0x36c 0x614 0x02 0x01 0x1d2 0x110 0x370 0x618 0x02 0x01 0x1d2 0x114 0x374 0x61c 0x02 0x01 0x1d2 0x11c 0x37c 0x620 0x02 0x01 0x1d2 0x124 0x384 0x604 0x02 0x01 0x196 0x128 0x388 0x60c 0x02 0x01 0x1d6>;
					phandle = <0x53>;
				};

				wdoggrp {
					fsl,pins = <0x1c 0x27c 0x00 0x01 0x00 0xc6>;
					phandle = <0x1a>;
				};

				bluetoothctrlgrp {
					fsl,pins = <0xac 0x30c 0x00 0x05 0x00 0x1c4>;
					phandle = <0xcf>;
				};

				wifictrlgrp {
					fsl,pins = <0xb0 0x310 0x00 0x05 0x00 0x1c4>;
					phandle = <0xd0>;
				};

				wifii2sgrp {
					fsl,pins = <0x19c 0x3fc 0x00 0x05 0x00 0x1d6 0x134 0x394 0x00 0x05 0x00 0x96 0x13c 0x39c 0x00 0x05 0x00 0x1d6 0x140 0x3a0 0x00 0x05 0x00 0x1d6>;
					phandle = <0xd1>;
				};

				wifipwrengrp {
					fsl,pins = <0xb8 0x318 0x00 0x05 0x00 0x184>;
					phandle = <0xd2>;
				};
			};

			iomuxc-gpr@30340000 {
				compatible = "fsl,imx8mp-iomuxc-gpr", "fsl,imx6q-iomuxc-gpr", "syscon";
				reg = <0x30340000 0x10000>;
				phandle = <0x32>;
			};

			efuse@30350000 {
				compatible = "fsl,imx8mp-ocotp", "fsl,imx8mm-ocotp", "syscon", "simple-mfd";
				reg = <0x30350000 0x10000>;
				clocks = <0x02 0xd6>;
				#address-cells = <0x01>;
				#size-cells = <0x01>;
				phandle = <0xd3>;

				unique-id@8 {
					reg = <0x08 0x08>;
					phandle = <0x17>;
				};

				speed-grade@10 {
					reg = <0x10 0x04>;
					phandle = <0x04>;
				};

				mac-address@90 {
					reg = <0x90 0x06>;
					phandle = <0x55>;
				};

				mac-address@650 {
					reg = <0x96 0x06>;
					phandle = <0x59>;
				};

				imx8mp-soc {
					compatible = "fsl,imx8mp-soc";
					nvmem-cells = <0x17>;
					nvmem-cell-names = "soc_unique_id";
					phandle = <0xd4>;
				};
			};

			anatop@30360000 {
				compatible = "fsl,imx8mp-anatop", "fsl,imx8mm-anatop", "syscon";
				reg = <0x30360000 0x10000>;
				phandle = <0xd5>;
			};

			caam_secvio {
				compatible = "fsl,imx6q-caam-secvio";
				interrupts = <0x00 0x14 0x04>;
				jtag-tamper = "disabled";
				watchdog-tamper = "enabled";
				internal-boot-tamper = "enabled";
				external-pin-tamper = "disabled";
				phandle = <0xd6>;
			};

			caam-snvs@30370000 {
				compatible = "fsl,imx6q-caam-snvs";
				reg = <0x30370000 0x10000>;
				clocks = <0x02 0xf9>;
				clock-names = "ipg";
				phandle = <0xd7>;
			};

			snvs@30370000 {
				compatible = "fsl,sec-v4.0-mon", "syscon", "simple-mfd";
				reg = <0x30370000 0x10000>;
				phandle = <0x22>;

				snvs-rtc-lp {
					compatible = "fsl,sec-v4.0-mon-rtc-lp";
					regmap = <0x22>;
					offset = <0x34>;
					interrupts = <0x00 0x13 0x04 0x00 0x14 0x04>;
					clocks = <0x02 0xf9>;
					clock-names = "snvs-rtc";
					phandle = <0xd8>;
				};

				snvs-powerkey {
					compatible = "fsl,sec-v4.0-pwrkey";
					regmap = <0x22>;
					interrupts = <0x00 0x04 0x04>;
					clocks = <0x02 0xf9>;
					clock-names = "snvs-pwrkey";
					linux,keycode = <0x74>;
					wakeup-source;
					status = "okay";
					phandle = <0xd9>;
				};
			};

			clock-controller@30380000 {
				compatible = "fsl,imx8mp-ccm";
				reg = <0x30380000 0x10000>;
				#clock-cells = <0x01>;
				clocks = <0x23 0x24 0x25 0x26 0x27 0x28>;
				clock-names = "osc_32k", "osc_24m", "clk_ext1", "clk_ext2", "clk_ext3", "clk_ext4";
				assigned-clocks = <0x02 0x42 0x02 0x120 0x02 0x67 0x02 0x68 0x02 0x94 0x02 0x6c 0x02 0x48 0x02 0x12 0x02 0x13 0x02 0x14>;
				assigned-clock-parents = <0x02 0x38 0x02 0x2c 0x02 0x41 0x02 0x38 0x02 0x40 0x02 0x38 0x02 0x38>;
				assigned-clock-rates = <0x00 0x00 0x3b9aca00 0x2faf0800 0x1dcd6500 0x17d78400 0x2faf0800 0x17700000 0x15888000 0x3df582e0>;
				phandle = <0x02>;
			};

			reset-controller@30390000 {
				compatible = "fsl,imx8mp-src", "syscon";
				reg = <0x30390000 0x10000>;
				interrupts = <0x00 0x59 0x04>;
				#reset-cells = <0x01>;
				phandle = <0x79>;
			};
		};

		bus@30400000 {
			compatible = "fsl,aips-bus", "simple-bus";
			reg = <0x30400000 0x100000>;
			#address-cells = <0x01>;
			#size-cells = <0x01>;
			ranges;
			phandle = <0xda>;

			pwm@30660000 {
				compatible = "fsl,imx8mp-pwm", "fsl,imx27-pwm";
				reg = <0x30660000 0x10000>;
				interrupts = <0x00 0x51 0x04>;
				clocks = <0x02 0xdc 0x02 0xdc>;
				clock-names = "ipg", "per";
				#pwm-cells = <0x03>;
				status = "okay";
				pinctrl-names = "default";
				pinctrl-0 = <0x29>;
				phandle = <0xdb>;
			};

			pwm@30670000 {
				compatible = "fsl,imx8mp-pwm", "fsl,imx27-pwm";
				reg = <0x30670000 0x10000>;
				interrupts = <0x00 0x52 0x04>;
				clocks = <0x02 0xdd 0x02 0xdd>;
				clock-names = "ipg", "per";
				#pwm-cells = <0x03>;
				status = "okay";
				pinctrl-names = "default";
				pinctrl-0 = <0x2a>;
				phandle = <0xa0>;
			};

			pwm@30680000 {
				compatible = "fsl,imx8mp-pwm", "fsl,imx27-pwm";
				reg = <0x30680000 0x10000>;
				interrupts = <0x00 0x53 0x04>;
				clocks = <0x02 0xde 0x02 0xde>;
				clock-names = "ipg", "per";
				#pwm-cells = <0x03>;
				status = "okay";
				pinctrl-names = "default";
				pinctrl-0 = <0x2b>;
				phandle = <0x9f>;
			};

			pwm@30690000 {
				compatible = "fsl,imx8mp-pwm", "fsl,imx27-pwm";
				reg = <0x30690000 0x10000>;
				interrupts = <0x00 0x54 0x04>;
				clocks = <0x02 0xdf 0x02 0xdf>;
				clock-names = "ipg", "per";
				#pwm-cells = <0x02>;
				status = "disabled";
				phandle = <0xdc>;
			};

			timer@306a0000 {
				compatible = "nxp,sysctr-timer";
				reg = <0x306a0000 0x20000>;
				interrupts = <0x00 0x2f 0x04>;
				clocks = <0x24>;
				clock-names = "per";
				phandle = <0xdd>;
			};
		};

		bus@30800000 {
			compatible = "fsl,aips-bus", "simple-bus";
			reg = <0x30800000 0x100000>;
			#address-cells = <0x01>;
			#size-cells = <0x01>;
			ranges;
			phandle = <0xde>;

			spi@30820000 {
				#address-cells = <0x01>;
				#size-cells = <0x00>;
				compatible = "fsl,imx8mp-ecspi", "fsl,imx6ul-ecspi";
				reg = <0x30820000 0x10000>;
				interrupts = <0x00 0x1f 0x04>;
				clocks = <0x02 0xbd 0x02 0xbd>;
				clock-names = "ipg", "per";
				assigned-clock-rates = <0x4c4b400>;
				assigned-clocks = <0x02 0x95>;
				assigned-clock-parents = <0x02 0x38>;
				dmas = <0x2c 0x00 0x07 0x01 0x2c 0x01 0x07 0x02>;
				dma-names = "rx", "tx";
				status = "okay";

				cs-gpios = <
					&0x2d 6 0 /* CS0 */				/* gpio@30200000 gpio0 */
													/* SOM PIN 212 = GPIO_4 CPU PIN GPIO1_IO06 */
													/* OK, this one is actualy FPGA_CS on Voyant SCH! */
													

					&0x2d 1 1 /* CS1 */				/* SOM PIN 208 = GPIO_2 CPU PIN GPIO1_IO01 */
													/* This one is ~{MS:PWRMON_DAC_CS on schamtic! */




					&pinctrl_gpio4 9 1 /* CS2 */	/* ECSPI1_SS0 Pin Active HIGH -josh */	
				>;
				num-cs = <4>;

				pinctrl-names = "default";
				pinctrl-0 = <0x2e &pinctrl_ecspi1_cs3>;
				phandle = <0xdf>;

				spidev@0 {
					compatible = "rohm,dh2228fv";
					reg = <0x00>;
					spi-max-frequency = <0x989680>;
				};

				spidev@1 {
					compatible = "rohm,dh2228fv";
					reg = <0x01>;
					spi-max-frequency = <0x989680>;
				};

				spidev@2 {
					compatible = "rohm,dh2228fv";
					reg = <0x02>;
					spi-max-frequency = <0x989680>;
				};

			};

			spi@30830000 {
				#address-cells = <0x01>;
				#size-cells = <0x00>;
				compatible = "fsl,imx8mp-ecspi", "fsl,imx6ul-ecspi";
				reg = <0x30830000 0x10000>;
				interrupts = <0x00 0x20 0x04>;
				clocks = <0x02 0xbe 0x02 0xbe>;
				clock-names = "ipg", "per";
				assigned-clock-rates = <0x4c4b400>;
				assigned-clocks = <0x02 0x96>;
				assigned-clock-parents = <0x02 0x38>;
				dmas = <0x2c 0x02 0x07 0x01 0x2c 0x03 0x07 0x02>;
				dma-names = "rx", "tx";
				status = "disabled";
				phandle = <0xe0>;
			};

			spi@30840000 {
				#address-cells = <0x01>;
				#size-cells = <0x00>;
				compatible = "fsl,imx8mp-ecspi", "fsl,imx6ul-ecspi";
				reg = <0x30840000 0x10000>;
				interrupts = <0x00 0x21 0x04>;
				clocks = <0x02 0xbf 0x02 0xbf>;
				clock-names = "ipg", "per";
				assigned-clock-rates = <0x4c4b400>;
				assigned-clocks = <0x02 0xb3>;
				assigned-clock-parents = <0x02 0x38>;
				dmas = <0x2c 0x04 0x07 0x01 0x2c 0x05 0x07 0x02>;
				dma-names = "rx", "tx";
				status = "disabled";
				phandle = <0xe1>;
			};

			serial@30860000 {
				compatible = "fsl,imx8mp-uart", "fsl,imx6q-uart";
				reg = <0x30860000 0x10000>;
				interrupts = <0x00 0x1a 0x04>;
				clocks = <0x02 0xfb 0x02 0xfb>;
				clock-names = "ipg", "per";
				dmas = <0x2c 0x16 0x04 0x00 0x2c 0x17 0x04 0x00>;
				dma-names = "rx", "tx";
				status = "okay";
				pinctrl-names = "default";
				pinctrl-0 = <0x2f>;
				uart-has-rtscts;
				phandle = <0xe2>;
			};

			serial@30880000 {
				compatible = "fsl,imx8mp-uart", "fsl,imx6q-uart";
				reg = <0x30880000 0x10000>;
				interrupts = <0x00 0x1c 0x04>;
				clocks = <0x02 0xfd 0x02 0xfd>;
				clock-names = "ipg", "per";
				dmas = <0x2c 0x1a 0x04 0x00 0x2c 0x1b 0x04 0x00>;
				dma-names = "rx", "tx";
				status = "okay";
				pinctrl-names = "default";
				pinctrl-0 = <0x30>;
				phandle = <0xe3>;
			};

			serial@30890000 {
				compatible = "fsl,imx8mp-uart", "fsl,imx6q-uart";
				reg = <0x30890000 0x10000>;
				interrupts = <0x00 0x1b 0x04>;
				clocks = <0x02 0xfc 0x02 0xfc>;
				clock-names = "ipg", "per";
				status = "disabled";
				pinctrl-names = "default";
				pinctrl-0 = <0x31>;
				uart-has-rtscts;
				phandle = <0xe4>;
			};

			can@308c0000 {
				compatible = "fsl,imx8mp-flexcan";
				reg = <0x308c0000 0x10000>;
				interrupts = <0x00 0x8e 0x04>;
				clocks = <0x02 0x6e 0x02 0xe9>;
				clock-names = "ipg", "per";
				assigned-clocks = <0x02 0x74>;
				assigned-clock-parents = <0x02 0x30>;
				assigned-clock-rates = <0x2625a00>;
				fsl,clk-source = [00];
				fsl,stop-mode = <0x32 0x10 0x04>;
				status = "okay";
				pinctrl-names = "default";
				pinctrl-0 = <0x33>;
				phandle = <0xe5>;
			};

			can@308d0000 {
				compatible = "fsl,imx8mp-flexcan";
				reg = <0x308d0000 0x10000>;
				interrupts = <0x00 0x90 0x04>;
				clocks = <0x02 0x6e 0x02 0xea>;
				clock-names = "ipg", "per";
				assigned-clocks = <0x02 0x75>;
				assigned-clock-parents = <0x02 0x30>;
				assigned-clock-rates = <0x2625a00>;
				fsl,clk-source = [00];
				fsl,stop-mode = <0x32 0x10 0x05>;
				status = "okay";
				pinctrl-names = "default";
				pinctrl-0 = <0x34>;
				phandle = <0xe6>;
			};

			crypto@30900000 {
				compatible = "fsl,sec-v4.0";
				#address-cells = <0x01>;
				#size-cells = <0x01>;
				reg = <0x30900000 0x40000>;
				ranges = <0x00 0x30900000 0x40000>;
				interrupts = <0x00 0x5b 0x04>;
				clocks = <0x02 0x6b 0x02 0x6e>;
				clock-names = "aclk", "ipg";
				phandle = <0xe7>;

				jr@1000 {
					compatible = "fsl,sec-v4.0-job-ring";
					reg = <0x1000 0x1000>;
					interrupts = <0x00 0x69 0x04>;
					status = "disabled";
					phandle = <0xe8>;
				};

				jr@2000 {
					compatible = "fsl,sec-v4.0-job-ring";
					reg = <0x2000 0x1000>;
					interrupts = <0x00 0x6a 0x04>;
					phandle = <0xe9>;
				};

				jr@3000 {
					compatible = "fsl,sec-v4.0-job-ring";
					reg = <0x3000 0x1000>;
					interrupts = <0x00 0x72 0x04>;
					phandle = <0xea>;
				};
			};

			i2c@30a20000 {
				compatible = "fsl,imx8mp-i2c", "fsl,imx21-i2c";
				#address-cells = <0x01>;
				#size-cells = <0x00>;
				reg = <0x30a20000 0x10000>;
				interrupts = <0x00 0x23 0x04>;
				clocks = <0x02 0xcd>;
				status = "okay";
				clock-frequency = <0x61a80>;
				pinctrl-names = "default", "gpio";
				pinctrl-0 = <0x35>;
				pinctrl-1 = <0x36>;
				scl-gpios = <0x37 0x0e 0x06>;
				sda-gpios = <0x37 0x0f 0x06>;
				single-master;
				phandle = <0xeb>;

				pmic@25 {
					compatible = "nxp,pca9450c";
					interrupt-parent = <0x2d>;
					interrupts = <0x03 0x08>;
					pinctrl-names = "default";
					pinctrl-0 = <0x38>;
					reg = <0x25>;
					sd-vsel-gpios = <0x2d 0x04 0x00>;
					phandle = <0xec>;

					regulators {

						BUCK1 {
							regulator-always-on;
							regulator-boot-on;
							regulator-max-microvolt = <0xf4240>;
							regulator-min-microvolt = <0xafc80>;
							regulator-name = "On-module +VDD_SOC (BUCK1)";
							regulator-ramp-delay = <0xc35>;
						};

						BUCK2 {
							nxp,dvs-run-voltage = <0xe7ef0>;
							nxp,dvs-standby-voltage = <0xcf850>;
							regulator-always-on;
							regulator-boot-on;
							regulator-max-microvolt = <0xfa3e8>;
							regulator-min-microvolt = <0xafc80>;
							regulator-name = "On-module +VDD_ARM (BUCK2)";
							regulator-ramp-delay = <0xc35>;
							phandle = <0x07>;
						};

						BUCK4 {
							regulator-always-on;
							regulator-boot-on;
							regulator-max-microvolt = <0x325aa0>;
							regulator-min-microvolt = <0x325aa0>;
							regulator-name = "On-module +V3.3 (BUCK4)";
							phandle = <0xaa>;
						};

						BUCK5 {
							regulator-always-on;
							regulator-boot-on;
							regulator-max-microvolt = <0x1b7740>;
							regulator-min-microvolt = <0x1b7740>;
							regulator-name = "PWR_1V8_MOCI (BUCK5)";
							phandle = <0x39>;
						};

						BUCK6 {
							regulator-always-on;
							regulator-boot-on;
							regulator-max-microvolt = <0x119fb8>;
							regulator-min-microvolt = <0xff208>;
							regulator-name = "On-module +VDD_DDR (BUCK6)";
						};

						LDO1 {
							regulator-always-on;
							regulator-boot-on;
							regulator-max-microvolt = <0x1dc130>;
							regulator-min-microvolt = <0x192d50>;
							regulator-name = "On-module +V1.8_SNVS (LDO1)";
						};

						LDO2 {
							regulator-always-on;
							regulator-boot-on;
							regulator-max-microvolt = <0x118c30>;
							regulator-min-microvolt = "", "\f5";
							regulator-name = "On-module +V0.8_SNVS (LDO2)";
						};

						LDO3 {
							regulator-always-on;
							regulator-boot-on;
							regulator-max-microvolt = <0x1b7740>;
							regulator-min-microvolt = <0x1b7740>;
							regulator-name = "On-module +V1.8A (LDO3)";
						};

						LDO4 {
							regulator-always-on;
							regulator-boot-on;
							regulator-max-microvolt = <0x325aa0>;
							regulator-min-microvolt = <0x325aa0>;
							regulator-name = "On-module +V3.3_ADC (LDO4)";
						};

						LDO5 {
							regulator-max-microvolt = <0x325aa0>;
							regulator-min-microvolt = <0x1b7740>;
							regulator-name = "On-module +V3.3_1.8_SD (LDO5)";
						};
					};
				};

				rtc@32 {
					compatible = "epson,rx8130";
					reg = <0x32>;
					phandle = <0xed>;
				};

				sensor@48 {
					compatible = "ti,tmp1075";
					reg = <0x48>;
					vs-supply = <0x39>;
					phandle = <0xee>;
				};

				adc@49 {
					compatible = "ti,ads1015";
					reg = <0x49>;
					#address-cells = <0x01>;
					#size-cells = <0x00>;

					channel@0 {
						reg = <0x00>;
						ti,datarate = <0x04>;
						ti,gain = <0x02>;
					};

					channel@1 {
						reg = <0x01>;
						ti,datarate = <0x04>;
						ti,gain = <0x02>;
					};

					channel@2 {
						reg = <0x02>;
						ti,datarate = <0x04>;
						ti,gain = <0x02>;
					};

					channel@3 {
						reg = <0x03>;
						ti,datarate = <0x04>;
						ti,gain = <0x02>;
					};

					channel@4 {
						reg = <0x04>;
						ti,datarate = <0x04>;
						ti,gain = <0x02>;
					};

					channel@5 {
						reg = <0x05>;
						ti,datarate = <0x04>;
						ti,gain = <0x02>;
					};

					channel@6 {
						reg = <0x06>;
						ti,datarate = <0x04>;
						ti,gain = <0x02>;
					};

					channel@7 {
						reg = <0x07>;
						ti,datarate = <0x04>;
						ti,gain = <0x02>;
					};
				};

				eeprom@50 {
					compatible = "st,24c02";
					pagesize = <0x10>;
					reg = <0x50>;
				};
			};

			i2c@30a30000 {
				compatible = "fsl,imx8mp-i2c", "fsl,imx21-i2c";
				#address-cells = <0x01>;
				#size-cells = <0x00>;
				reg = <0x30a30000 0x10000>;
				interrupts = <0x00 0x24 0x04>;
				clocks = <0x02 0xce>;
				status = "disabled";
				clock-frequency = <0x61a80>;
				pinctrl-names = "default", "gpio";
				pinctrl-0 = <0x3a>;
				pinctrl-1 = <0x3b>;
				scl-gpios = <0x37 0x10 0x06>;
				sda-gpios = <0x37 0x11 0x06>;
				single-master;
				phandle = <0xa2>;

				touch-mezzanine@4a {
					compatible = "atmel,maxtouch";
					interrupt-parent = <0x2d>;
					interrupts = <0x05 0x02>;
					reg = <0x4a>;
					reset-gpios = <0x2d 0x01 0x01>;
					status = "disabled";
					phandle = <0xef>;
				};
			};

			i2c@30a40000 {
				compatible = "fsl,imx8mp-i2c", "fsl,imx21-i2c";
				#address-cells = <0x01>;
				#size-cells = <0x00>;
				reg = <0x30a40000 0x10000>;
				interrupts = <0x00 0x25 0x04>;
				clocks = <0x02 0xcf>;
				status = "disabled";
				clock-frequency = <0x61a80>;
				pinctrl-names = "default", "gpio";
				pinctrl-0 = <0x3c>;
				pinctrl-1 = <0x3d>;
				scl-gpios = <0x37 0x12 0x06>;
				sda-gpios = <0x37 0x13 0x06>;
				single-master;
				phandle = <0xf0>;
			};

			i2c@30a50000 {
				compatible = "fsl,imx8mp-i2c", "fsl,imx21-i2c";
				#address-cells = <0x01>;
				#size-cells = <0x00>;
				reg = <0x30a50000 0x10000>;
				interrupts = <0x00 0x26 0x04>;
				clocks = <0x02 0xd0>;
				status = "okay";
				clock-frequency = <0x61a80>;
				pinctrl-names = "default", "gpio";
				pinctrl-0 = <0x3e>;
				pinctrl-1 = <0x3f>;
				scl-gpios = <0x37 0x14 0x06>;
				sda-gpios = <0x37 0x15 0x06>;
				single-master;
				phandle = <0xf1>;

				gpio-expander@21 {
					compatible = "nxp,pcal6416";
					#gpio-cells = <0x02>;
					gpio-controller;
					reg = <0x21>;
					vcc-supply = <0x40>;
					status = "disabled";
					phandle = <0xf2>;
				};

				bridge@2c {
					compatible = "ti,sn65dsi84";
					enable-gpios = <0x41 0x1c 0x00>;
					pinctrl-names = "default";
					pinctrl-0 = <0x42>;
					reg = <0x2c>;
					status = "disabled";
					phandle = <0xf3>;
				};

				hwmon@40 {
					compatible = "ti,ina219";
					reg = <0x40>;
					shunt-resistor = <0x2710>;
					status = "okay";
					phandle = <0xf4>;
				};

				hdmi@48 {
					compatible = "lontium,lt8912b";
					pinctrl-names = "default";
					pinctrl-0 = <0x42>;
					reg = <0x48>;
					reset-gpios = <0x41 0x1c 0x01>;
					status = "disabled";
					phandle = <0xf5>;
				};

				touch@4a {
					compatible = "atmel,maxtouch";
					interrupt-parent = <0x41>;
					interrupts = <0x19 0x02>;
					pinctrl-names = "default";
					pinctrl-0 = <0x43 0x44>;
					reg = <0x4a>;
					reset-gpios = <0x37 0x00 0x01>;
					status = "disabled";
					phandle = <0xf6>;
				};

				sensor@4f {
					compatible = "ti,tmp75c";
					reg = <0x4f>;
					status = "okay";
					vs-supply = <0x45>;
					phandle = <0xf7>;
				};

				eeprom@50 {
					compatible = "st,24c02";
					pagesize = <0x10>;
					reg = <0x50>;
					status = "okay";
					phandle = <0xf8>;
				};

				eeprom@57 {
					compatible = "st,24c02";
					pagesize = <0x10>;
					reg = <0x57>;
					status = "okay";
					phandle = <0xf9>;
				};

				audio-codec@1a {
					compatible = "wlf,wm8904";
					reg = <0x1a>;
					pinctrl-names = "default";
					pinctrl-0 = <0x46>;
					#sound-dai-cells = <0x00>;
					clocks = <0x47 0x01>;
					clock-names = "mclk";
					AVDD-supply = <0x45>;
					CPVDD-supply = <0x45>;
					DBVDD-supply = <0x45>;
					DCVDD-supply = <0x45>;
					MICVDD-supply = <0x45>;
					phandle = <0xaf>;
				};
			};

			serial@30a60000 {
				compatible = "fsl,imx8mp-uart", "fsl,imx6q-uart";
				reg = <0x30a60000 0x10000>;
				interrupts = <0x00 0x1d 0x04>;
				clocks = <0x02 0xfe 0x02 0xfe>;
				clock-names = "ipg", "per";
				dmas = <0x2c 0x1c 0x04 0x00 0x2c 0x1d 0x04 0x00>;
				dma-names = "rx", "tx";
				status = "disabled";
				pinctrl-names = "default";
				pinctrl-0 = <0x48>;
				phandle = <0xfa>;
			};

			mailbox@30aa0000 {
				compatible = "fsl,imx8mp-mu", "fsl,imx6sx-mu";
				reg = <0x30aa0000 0x10000>;
				interrupts = <0x00 0x58 0x04>;
				clocks = <0x02 0xd5>;
				#mbox-cells = <0x02>;
				phandle = <0xfb>;
			};

			i2c@30ad0000 {
				compatible = "fsl,imx8mp-i2c", "fsl,imx21-i2c";
				#address-cells = <0x01>;
				#size-cells = <0x00>;
				reg = <0x30ad0000 0x10000>;
				interrupts = <0x00 0x4c 0x04>;
				clocks = <0x02 0xe7>;
				status = "disabled";
				phandle = <0xfc>;
			};

			i2c@30ae0000 {
				compatible = "fsl,imx8mp-i2c", "fsl,imx21-i2c";
				#address-cells = <0x01>;
				#size-cells = <0x00>;
				reg = <0x30ae0000 0x10000>;
				interrupts = <0x00 0x4d 0x04>;
				clocks = <0x02 0xe8>;
				status = "disabled";
				phandle = <0xfd>;
			};

			mmc@30b40000 {
				compatible = "fsl,imx8mp-usdhc", "fsl,imx8mm-usdhc";
				reg = <0x30b40000 0x10000>;
				interrupts = <0x00 0x16 0x04>;
				clocks = <0x02 0x00 0x02 0x5f 0x02 0x101>;
				clock-names = "ipg", "ahb", "per";
				fsl,tuning-start-tap = <0x14>;
				fsl,tuning-step = <0x02>;
				bus-width = <0x04>;
				status = "disabled";
				phandle = <0xfe>;
			};

			mmc@30b50000 {
				compatible = "fsl,imx8mp-usdhc", "fsl,imx8mm-usdhc";
				reg = <0x30b50000 0x10000>;
				interrupts = <0x00 0x17 0x04>;
				clocks = <0x02 0x00 0x02 0x5f 0x02 0x102>;
				clock-names = "ipg", "ahb", "per";
				fsl,tuning-start-tap = <0x14>;
				fsl,tuning-step = <0x02>;
				bus-width = <0x04>;
				status = "okay";
				assigned-clocks = <0x02 0x89>;
				assigned-clock-rates = <0x17d78400>;
				cd-gpios = <0x49 0x0c 0x01>;
				disable-wp;
				pinctrl-names = "default", "state_100mhz", "state_200mhz", "sleep";
				pinctrl-0 = <0x4a 0x4b>;
				pinctrl-1 = <0x4c 0x4b>;
				pinctrl-2 = <0x4d 0x4b>;
				pinctrl-3 = <0x4e 0x4f>;
				vmmc-supply = <0x50>;
				phandle = <0xff>;
			};

			mmc@30b60000 {
				compatible = "fsl,imx8mp-usdhc", "fsl,imx8mm-usdhc";
				reg = <0x30b60000 0x10000>;
				interrupts = <0x00 0x18 0x04>;
				clocks = <0x02 0x00 0x02 0x5f 0x02 0x115>;
				clock-names = "ipg", "ahb", "per";
				fsl,tuning-start-tap = <0x14>;
				fsl,tuning-step = <0x02>;
				bus-width = <0x08>;
				status = "okay";
				assigned-clocks = <0x02 0x115>;
				assigned-clock-rates = <0x17d78400>;
				non-removable;
				pinctrl-names = "default", "state_100mhz", "state_200mhz";
				pinctrl-0 = <0x51>;
				pinctrl-1 = <0x52>;
				pinctrl-2 = <0x53>;
				phandle = <0x100>;
			};

			spi@30bb0000 {
				compatible = "nxp,imx8mp-fspi";
				reg = <0x30bb0000 0x10000 0x8000000 0x10000000>;
				reg-names = "fspi_base", "fspi_mmap";
				interrupts = <0x00 0x6b 0x04>;
				clocks = <0x02 0xe2 0x02 0xe2>;
				clock-names = "fspi", "fspi_en";
				assigned-clock-rates = <0x4c4b400>;
				assigned-clocks = <0x02 0x87>;
				#address-cells = <0x01>;
				#size-cells = <0x00>;
				status = "okay";
				pinctrl-names = "default";
				pinctrl-0 = <0x54>;
				phandle = <0x101>;
			};

			dma-controller@30bd0000 {
				compatible = "fsl,imx8mq-sdma";
				reg = <0x30bd0000 0x10000>;
				interrupts = <0x00 0x02 0x04>;
				clocks = <0x02 0xec 0x02 0x6b>;
				clock-names = "ipg", "ahb";
				#dma-cells = <0x03>;
				fsl,sdma-ram-script-name = "imx/sdma/sdma-imx7d.bin";
				phandle = <0x2c>;
			};

			ethernet@30be0000 {
				compatible = "fsl,imx8mp-fec", "fsl,imx8mq-fec", "fsl,imx6sx-fec";
				reg = <0x30be0000 0x10000>;
				interrupts = <0x00 0x76 0x04 0x00 0x77 0x04 0x00 0x78 0x04 0x00 0x79 0x04>;
				clocks = <0x02 0xc0 0x02 0xf2 0x02 0x84 0x02 0x83 0x02 0x85>;
				clock-names = "ipg", "ahb", "ptp", "enet_clk_ref", "enet_out";
				assigned-clocks = <0x02 0x5e 0x02 0x84 0x02 0x83 0x02 0x85>;
				assigned-clock-parents = <0x02 0x36 0x02 0x3a 0x02 0x3b 0x02 0x39>;
				assigned-clock-rates = <0x00 0x5f5e100 0x7735940 0x00>;
				fsl,num-tx-queues = <0x03>;
				fsl,num-rx-queues = <0x03>;
				nvmem-cells = <0x55>;
				nvmem-cell-names = "mac-address";
				fsl,stop-mode = <0x32 0x10 0x03>;
				nvmem_macaddr_swap;
				status = "disabled";
				fsl,magic-packet;
				phy-handle = <0x56>;
				phy-mode = "rgmii-id";
				pinctrl-names = "default", "sleep";
				pinctrl-0 = <0x57>;
				pinctrl-1 = <0x58>;
				phandle = <0x102>;

				mdio {
					#address-cells = <0x01>;
					#size-cells = <0x00>;

					ethernet-phy@7 {
						compatible = "ethernet-phy-ieee802.3-c22";
						interrupt-parent = <0x41>;
						interrupts = <0x12 0x08>;
						micrel,led-mode = <0x00>;
						reg = <0x07>;
						phandle = <0x56>;
					};
				};
			};

			ethernet@30bf0000 {
				compatible = "nxp,imx8mp-dwmac-eqos", "snps,dwmac-5.10a";
				reg = <0x30bf0000 0x10000>;
				interrupts = <0x00 0x87 0x04 0x00 0x86 0x04>;
				interrupt-names = "macirq", "eth_wake_irq";
				clocks = <0x02 0xed 0x02 0xe1 0x02 0x82 0x02 0x81>;
				clock-names = "stmmaceth", "pclk", "ptp_ref", "tx";
				assigned-clocks = <0x02 0x5e 0x02 0x82 0x02 0x81>;
				assigned-clock-parents = <0x02 0x36 0x02 0x3a 0x02 0x3b>;
				assigned-clock-rates = <0x00 0x5f5e100 0x7735940>;
				nvmem-cells = <0x59>;
				nvmem-cell-names = "mac-address";
				nvmem_macaddr_swap;
				intf_mode = <0x32 0x04>;
				status = "okay";
				phy-handle = <0x5a>;
				phy-mode = "rgmii-id";
				phy-supply = <0x5b>;
				pinctrl-names = "default";
				pinctrl-0 = <0x5c>;
				snps,force_thresh_dma_mode;
				snps,mtl-rx-config = <0x5d>;
				snps,mtl-tx-config = <0x5e>;
				phandle = <0x103>;

				mdio {
					compatible = "snps,dwmac-mdio";
					#address-cells = <0x01>;
					#size-cells = <0x00>;

					ethernet-phy@7 {
						compatible = "ethernet-phy-ieee802.3-c22";
						eee-broken-100tx;
						eee-broken-1000t;
						interrupt-parent = <0x2d>;
						interrupts = <0x0a 0x08>;
						micrel,led-mode = <0x00>;
						reg = <0x07>;
						phandle = <0x5a>;
					};
				};

				rx-queues-config {
					snps,rx-queues-to-use = <0x05>;
					snps,rx-sched-sp;
					phandle = <0x5d>;

					queue0 {
						snps,dcb-algorithm;
						snps,priority = <0x01>;
						snps,map-to-dma-channel = <0x00>;
					};

					queue1 {
						snps,dcb-algorithm;
						snps,priority = <0x02>;
						snps,map-to-dma-channel = <0x01>;
					};

					queue2 {
						snps,dcb-algorithm;
						snps,priority = <0x04>;
						snps,map-to-dma-channel = <0x02>;
					};

					queue3 {
						snps,dcb-algorithm;
						snps,priority = <0x08>;
						snps,map-to-dma-channel = <0x03>;
					};

					queue4 {
						snps,dcb-algorithm;
						snps,priority = <0xf0>;
						snps,map-to-dma-channel = <0x04>;
					};
				};

				tx-queues-config {
					snps,tx-queues-to-use = <0x05>;
					snps,tx-sched-sp;
					phandle = <0x5e>;

					queue0 {
						snps,dcb-algorithm;
						snps,priority = <0x01>;
					};

					queue1 {
						snps,dcb-algorithm;
						snps,priority = <0x02>;
					};

					queue2 {
						snps,dcb-algorithm;
						snps,priority = <0x04>;
					};

					queue3 {
						snps,dcb-algorithm;
						snps,priority = <0x08>;
					};

					queue4 {
						snps,dcb-algorithm;
						snps,priority = <0xf0>;
					};
				};
			};
		};

		bus@32c00000 {
			compatible = "simple-bus";
			reg = <0x32c00000 0x400000>;
			#address-cells = <0x01>;
			#size-cells = <0x01>;
			ranges;
			phandle = <0x104>;

			mipi_dsi@32e60000 {
				#address-cells = <0x01>;
				#size-cells = <0x00>;
				compatible = "fsl,imx8mp-mipi-dsim";
				reg = <0x32e60000 0x10000>;
				clocks = <0x5f 0x00 0x5f 0x01>;
				clock-names = "cfg", "pll-ref";
				assigned-clocks = <0x02 0xab>;
				assigned-clock-parents = <0x02 0x02>;
				assigned-clock-rates = <0xb71b00>;
				interrupts = <0x00 0x12 0x04>;
				power-domains = <0x60>;
				status = "disabled";
				phandle = <0x105>;

				port@0 {

					endpoint {
						remote-endpoint = <0x61>;
						phandle = <0x62>;
					};
				};
			};

			lcd-controller@32e80000 {
				#address-cells = <0x01>;
				#size-cells = <0x00>;
				compatible = "fsl,imx8mp-lcdif1";
				reg = <0x32e80000 0x10000>;
				clocks = <0x5f 0x04 0x5f 0x17 0x5f 0x05>;
				clock-names = "pix", "disp-axi", "disp-apb";
				assigned-clocks = <0x02 0xac 0x02 0x61 0x02 0x62>;
				assigned-clock-parents = <0x02 0x28 0x02 0x41 0x02 0x38>;
				assigned-clock-rates = <0x00 0x1dcd6500 0xbebc200>;
				interrupts = <0x00 0x05 0x04>;
				blk-ctl = <0x5f>;
				resets = <0x5f 0x05>;
				power-domains = <0x0e>;
				status = "disabled";
				phandle = <0x106>;

				port@0 {
					reg = <0x00>;
					phandle = <0x08>;

					endpoint {
						remote-endpoint = <0x62>;
						phandle = <0x61>;
					};
				};
			};

			lcd-controller@32e90000 {
				#address-cells = <0x01>;
				#size-cells = <0x00>;
				compatible = "fsl,imx8mp-lcdif2";
				reg = <0x32e90000 0x10000>;
				clocks = <0x5f 0x0b 0x5f 0x18 0x5f 0x0c>;
				clock-names = "pix", "disp-axi", "disp-apb";
				assigned-clocks = <0x02 0x139 0x02 0x61 0x02 0x62>;
				assigned-clock-parents = <0x02 0x28 0x02 0x41 0x02 0x38>;
				assigned-clock-rates = <0x00 0x1dcd6500 0xbebc200>;
				interrupts = <0x00 0x06 0x04>;
				power-domains = <0x0e>;
				status = "disabled";
				phandle = <0x107>;

				port@0 {
					#address-cells = <0x01>;
					#size-cells = <0x00>;
					reg = <0x00>;
					phandle = <0x09>;

					endpoint@0 {
						reg = <0x00>;
						remote-endpoint = <0x63>;
						phandle = <0x66>;
					};

					endpoint@1 {
						reg = <0x01>;
						remote-endpoint = <0x64>;
						phandle = <0x69>;
					};
				};
			};

			media-blk-ctrl@32ec0000 {
				compatible = "fsl,imx8mp-media-blk-ctrl", "syscon";
				reg = <0x32ec0000 0x10000>;
				power-domains = <0x0e>;
				#clock-cells = <0x01>;
				#reset-cells = <0x01>;
				phandle = <0x5f>;
			};

			ldb@32ec005c {
				#address-cells = <0x01>;
				#size-cells = <0x00>;
				compatible = "fsl,imx8mp-ldb";
				clocks = <0x02 0x13a>;
				clock-names = "ldb";
				assigned-clocks = <0x02 0xae>;
				assigned-clock-parents = <0x02 0x28>;
				gpr = <0x5f>;
				power-domains = <0x0e>;
				status = "disabled";
				phandle = <0x108>;

				lvds-channel@0 {
					#address-cells = <0x01>;
					#size-cells = <0x00>;
					reg = <0x00>;
					phys = <0x65>;
					phy-names = "ldb_phy";
					status = "okay";
					fsl,data-mapping = "spwg";
					fsl,data-width = <0x18>;
					phandle = <0x109>;

					port@0 {
						reg = <0x00>;

						endpoint {
							remote-endpoint = <0x66>;
							phandle = <0x63>;
						};
					};

					port@1 {
						reg = <0x01>;

						endpoint {
							remote-endpoint = <0x67>;
							phandle = <0xa7>;
						};
					};
				};

				lvds-channel@1 {
					#address-cells = <0x01>;
					#size-cells = <0x00>;
					reg = <0x01>;
					phys = <0x68>;
					phy-names = "ldb_phy";
					status = "disabled";

					port@0 {
						reg = <0x00>;

						endpoint {
							remote-endpoint = <0x69>;
							phandle = <0x64>;
						};
					};
				};
			};

			phy@32ec0128 {
				compatible = "fsl,imx8mp-lvds-phy";
				#address-cells = <0x01>;
				#size-cells = <0x00>;
				gpr = <0x5f>;
				clocks = <0x02 0x10d>;
				clock-names = "apb";
				power-domains = <0x0e>;
				status = "disabled";
				phandle = <0x10a>;

				port@0 {
					reg = <0x00>;
					#phy-cells = <0x00>;
					phandle = <0x65>;
				};

				port@1 {
					reg = <0x01>;
					#phy-cells = <0x00>;
					phandle = <0x68>;
				};
			};

			media_gpr@32ec0008 {
				compatible = "fsl,imx8mp-iomuxc-gpr", "syscon";
				reg = <0x32ec0008 0x04>;
				phandle = <0x10b>;
			};

			gasket@32ec0060 {
				compatible = "fsl,imx8mp-iomuxc-gpr", "syscon";
				reg = <0x32ec0060 0x28>;
				phandle = <0x6c>;
			};

			gasket@32ec0090 {
				compatible = "fsl,imx8mp-iomuxc-gpr", "syscon";
				reg = <0x32ec0090 0x28>;
				phandle = <0x6d>;
			};

			isi_chain@32e02000 {
				compatible = "fsl,imx8mp-iomuxc-gpr", "syscon";
				reg = <0x32e02000 0x04>;
				phandle = <0x6a>;
			};

			camera {
				compatible = "fsl,mxc-md", "simple-bus";
				#address-cells = <0x01>;
				#size-cells = <0x01>;
				ranges;
				status = "disabled";
				phandle = <0x10c>;

				isi@32e00000 {
					compatible = "fsl,imx8mp-isi", "fsl,imx8mn-isi";
					reg = <0x32e00000 0x2000>;
					interrupts = <0x00 0x10 0x04>;
					interface = <0x02 0x00 0x02>;
					clocks = <0x02 0x61 0x02 0x62 0x02 0x10e 0x02 0x10d 0x5f 0x08 0x5f 0x06 0x5f 0x07>;
					clock-names = "disp_axi", "disp_apb", "disp_axi_root", "disp_apb_root", "media_blk_bus", "media_blk_isi_proc", "media_blk_isi_apb";
					assigned-clocks = <0x02 0x10e 0x02 0x10d>;
					assigned-clock-rates = <0x1dcd6500 0xbebc200>;
					resets = <0x5f 0x06 0x5f 0x07 0x5f 0x08>;
					reset-names = "isi_rst_proc", "isi_rst_apb", "isi_rst_bus";
					power-domains = <0x0e>;
					isi_chain = <0x6a>;
					status = "disabled";
					phandle = <0x10d>;

					cap_device {
						compatible = "imx-isi-capture";
						status = "disabled";
					};

					m2m_device {
						compatible = "imx-isi-m2m";
						status = "disabled";
					};
				};

				isi@32e02000 {
					compatible = "fsl,imx8mp-isi", "fsl,imx8mn-isi";
					reg = <0x32e02000 0x2000>;
					interrupts = <0x00 0x2a 0x04>;
					interface = <0x03 0x00 0x02>;
					clocks = <0x02 0x61 0x02 0x62 0x02 0x10e 0x02 0x10d 0x5f 0x08 0x5f 0x06 0x5f 0x07>;
					clock-names = "disp_axi", "disp_apb", "disp_axi_root", "disp_apb_root", "media_blk_bus", "media_blk_isi_proc", "media_blk_isi_apb";
					assigned-clocks = <0x02 0x10e 0x02 0x10d>;
					assigned-clock-rates = <0x1dcd6500 0xbebc200>;
					resets = <0x5f 0x06 0x5f 0x07 0x5f 0x08>;
					reset-names = "isi_rst_proc", "isi_rst_apb", "isi_rst_bus";
					power-domains = <0x0e>;
					status = "disabled";
					phandle = <0x10e>;

					cap_device {
						compatible = "imx-isi-capture";
						status = "disabled";
					};
				};

				dwe@32e30000 {
					compatible = "fsl,imx8mp-dwe";
					clocks = <0x5f 0x13 0x5f 0x14 0x5f 0x15>;
					clock-names = "core", "axi", "ahb";
					reg = <0x32e30000 0x10000>;
					interrupts = <0x00 0x64 0x04>;
					power-domains = <0x6b>;
					status = "disabled";
					phandle = <0x10f>;
				};

				isp@32e10000 {
					compatible = "fsl,imx8mp-isp";
					reg = <0x32e10000 0x10000>;
					interrupts = <0x00 0x4a 0x04>;
					clocks = <0x5f 0x10 0x5f 0x11 0x5f 0x12 0x5f 0x03>;
					clock-names = "core", "axi", "ahb", "sensor";
					assigned-clocks = <0x02 0x138>;
					assigned-clock-parents = <0x02 0x40>;
					assigned-clock-rates = <0x1dcd6500>;
					power-domains = <0x6b>;
					id = <0x00>;
					gpr = <0x5f>;
					status = "disabled";
					phandle = <0x110>;
				};

				isp@32e20000 {
					compatible = "fsl,imx8mp-isp";
					reg = <0x32e20000 0x10000>;
					interrupts = <0x00 0x4b 0x04>;
					clocks = <0x5f 0x10 0x5f 0x11 0x5f 0x12 0x5f 0x03>;
					clock-names = "core", "axi", "ahb", "sensor";
					assigned-clocks = <0x02 0x138>;
					assigned-clock-parents = <0x02 0x40>;
					assigned-clock-rates = <0x1dcd6500>;
					power-domains = <0x6b>;
					id = <0x01>;
					gpr = <0x5f>;
					status = "disabled";
					phandle = <0x111>;
				};

				csi@32e40000 {
					compatible = "fsl,imx8mp-mipi-csi", "fsl,imx8mn-mipi-csi";
					reg = <0x32e40000 0x10000>;
					interrupts = <0x00 0x11 0x04>;
					clock-frequency = <0x1dcd6500>;
					clocks = <0x02 0xaa 0x02 0x61 0x02 0x62 0x5f 0x02 0x5f 0x03>;
					clock-names = "mipi_clk", "disp_axi", "disp_apb", "media_blk_csi_pclk", "media_blk_csi_aclk";
					assigned-clocks = <0x02 0xaa>;
					assigned-clock-parents = <0x02 0x41>;
					assigned-clock-rates = <0x1dcd6500>;
					bus-width = <0x04>;
					csi-gpr = <0x6c>;
					gpr = <0x5f>;
					resets = <0x5f 0x02 0x5f 0x03>;
					reset-names = "csi_rst_pclk", "csi_rst_aclk";
					power-domains = <0x60>;
					status = "disabled";
					phandle = <0x112>;
				};

				csi@32e50000 {
					compatible = "fsl,imx8mp-mipi-csi", "fsl,imx8mn-mipi-csi";
					reg = <0x32e50000 0x10000>;
					interrupts = <0x00 0x50 0x04>;
					clock-frequency = <0xfdad680>;
					clocks = <0x02 0xad 0x02 0x61 0x02 0x62 0x5f 0x09 0x5f 0x0a>;
					clock-names = "mipi_clk", "disp_axi", "disp_apb", "media_blk_csi_pclk", "media_blk_csi_aclk";
					assigned-clocks = <0x02 0xad>;
					assigned-clock-parents = <0x02 0x36>;
					assigned-clock-rates = <0xfdad680>;
					bus-width = <0x04>;
					csi-gpr = <0x6d>;
					gpr = <0x5f>;
					resets = <0x5f 0x09 0x5f 0x0a>;
					reset-names = "csi_rst_pclk", "csi_rst_aclk";
					power-domains = <0x6e>;
					status = "disabled";
					phandle = <0x113>;
				};
			};

			pcie-phy@32f00000 {
				compatible = "fsl,imx8mp-pcie-phy";
				reg = <0x32f00000 0x10000>;
				clocks = <0x02 0x00>;
				clock-names = "phy";
				#phy-cells = <0x00>;
				status = "okay";
				ext_osc = <0x00>;
				phandle = <0x7a>;
			};

			hsio-mix@32f10000 {
				compatible = "fsl,imx8mp-hsio-mix";
				reg = <0x32f10000 0x08>;
				phandle = <0x7b>;
			};
		};

		bus@30c00000 {
			compatible = "fsl,aips-bus", "simple-bus";
			reg = <0x30c00000 0x10000>;
			#address-cells = <0x01>;
			#size-cells = <0x01>;
			ranges;
			phandle = <0x114>;

			spba-bus@30c00000 {
				compatible = "fsl,spba-bus", "simple-bus";
				reg = <0x30c00000 0x100000>;
				#address-cells = <0x01>;
				#size-cells = <0x01>;
				ranges;

				sai@30c10000 {
					compatible = "fsl,imx8mp-sai", "fsl,imx8mm-sai";
					reg = <0x30c10000 0x10000>;
					#sound-dai-cells = <0x00>;
					interrupts = <0x00 0x5f 0x04>;
					clocks = <0x47 0x00 0x02 0x00 0x47 0x01 0x02 0x00 0x02 0x00>;
					clock-names = "bus", "mclk0", "mclk1", "mclk2", "mclk3";
					dmas = <0x6f 0x00 0x02 0x00 0x6f 0x01 0x02 0x00>;
					dma-names = "rx", "tx";
					fsl,shared-interrupt;
					fsl,dataline = <0x00 0xff 0xff>;
					power-domains = <0x70>;
					status = "okay";
					assigned-clocks = <0x02 0x7b>;
					assigned-clock-parents = <0x02 0x26>;
					assigned-clock-rates = <0x1770000>;
					fsl,sai-mclk-direction-output;
					phandle = <0xb0>;
				};

				sai@30c20000 {
					compatible = "fsl,imx8mp-sai", "fsl,imx8mm-sai";
					reg = <0x30c20000 0x10000>;
					#sound-dai-cells = <0x00>;
					interrupts = <0x00 0x60 0x04>;
					clocks = <0x47 0x04 0x02 0x00 0x47 0x05 0x02 0x00 0x02 0x00>;
					clock-names = "bus", "mclk0", "mclk1", "mclk2", "mclk3";
					dmas = <0x6f 0x02 0x02 0x00 0x6f 0x03 0x02 0x00>;
					dma-names = "rx", "tx";
					fsl,shared-interrupt;
					fsl,dataline = <0x00 0x0f 0x0f>;
					power-domains = <0x70>;
					status = "disabled";
					phandle = <0x115>;
				};

				sai@30c30000 {
					compatible = "fsl,imx8mp-sai", "fsl,imx8mm-sai";
					reg = <0x30c30000 0x10000>;
					#sound-dai-cells = <0x00>;
					interrupts = <0x00 0x32 0x04>;
					clocks = <0x47 0x08 0x02 0x00 0x47 0x09 0x02 0x00 0x02 0x00>;
					clock-names = "bus", "mclk0", "mclk1", "mclk2", "mclk3";
					dmas = <0x6f 0x04 0x02 0x00 0x6f 0x05 0x02 0x00>;
					dma-names = "rx", "tx";
					fsl,shared-interrupt;
					fsl,dataline = <0x00 0x03 0x03>;
					power-domains = <0x70>;
					status = "disabled";
					phandle = <0x116>;
				};

				sai@30c50000 {
					compatible = "fsl,imx8mp-sai", "fsl,imx8mm-sai";
					reg = <0x30c50000 0x10000>;
					#sound-dai-cells = <0x00>;
					interrupts = <0x00 0x5a 0x04>;
					clocks = <0x47 0x0c 0x02 0x00 0x47 0x0d 0x02 0x00 0x02 0x00>;
					clock-names = "bus", "mclk0", "mclk1", "mclk2", "mclk3";
					dmas = <0x6f 0x08 0x02 0x00 0x6f 0x09 0x02 0x00>;
					dma-names = "rx", "tx";
					fsl,shared-interrupt;
					fsl,dataline = <0x00 0x0f 0x0f>;
					power-domains = <0x70>;
					status = "disabled";
					phandle = <0x117>;
				};

				sai@30c60000 {
					compatible = "fsl,imx8mp-sai", "fsl,imx8mm-sai";
					reg = <0x30c60000 0x10000>;
					#sound-dai-cells = <0x00>;
					interrupts = <0x00 0x5a 0x04>;
					clocks = <0x47 0x10 0x02 0x00 0x47 0x11 0x02 0x00 0x02 0x00>;
					clock-names = "bus", "mclk0", "mclk1", "mclk2", "mclk3";
					dmas = <0x6f 0x0a 0x02 0x00 0x6f 0x0b 0x02 0x00>;
					dma-names = "rx", "tx";
					fsl,shared-interrupt;
					power-domains = <0x70>;
					status = "disabled";
					phandle = <0x118>;
				};

				sai@30c80000 {
					compatible = "fsl,imx8mp-sai", "fsl,imx8mm-sai";
					reg = <0x30c80000 0x10000>;
					#sound-dai-cells = <0x00>;
					interrupts = <0x00 0x6f 0x04>;
					clocks = <0x47 0x14 0x02 0x00 0x47 0x15 0x02 0x00 0x02 0x00>;
					clock-names = "bus", "mclk0", "mclk1", "mclk2", "mclk3";
					dmas = <0x6f 0x0c 0x02 0x00 0x6f 0x0d 0x02 0x00>;
					dma-names = "rx", "tx";
					fsl,shared-interrupt;
					power-domains = <0x70>;
					status = "disabled";
					phandle = <0x119>;
				};

				easrc@30c90000 {
					compatible = "fsl,imx8mn-easrc";
					reg = <0x30c90000 0x10000>;
					interrupts = <0x00 0x7a 0x04>;
					clocks = <0x47 0x18>;
					clock-names = "mem";
					dmas = <0x6f 0x10 0x17 0x00 0x6f 0x11 0x17 0x00 0x6f 0x12 0x17 0x00 0x6f 0x13 0x17 0x00 0x6f 0x14 0x17 0x00 0x6f 0x15 0x17 0x00 0x6f 0x16 0x17 0x00 0x6f 0x17 0x17 0x00>;
					dma-names = "ctx0_rx", "ctx0_tx", "ctx1_rx", "ctx1_tx", "ctx2_rx", "ctx2_tx", "ctx3_rx", "ctx3_tx";
					firmware-name = "imx/easrc/easrc-imx8mn.bin";
					fsl,asrc-rate = <0x1f40>;
					fsl,asrc-width = <0x10>;
					power-domains = <0x70>;
					status = "disabled";
					phandle = <0x11a>;
				};

				micfil@30ca0000 {
					compatible = "fsl,imx8mp-micfil";
					reg = <0x30ca0000 0x10000>;
					interrupts = <0x00 0x6d 0x04 0x00 0x6e 0x04 0x00 0x2c 0x04 0x00 0x2d 0x04>;
					clocks = <0x47 0x19 0x47 0x27 0x02 0x26 0x02 0x27 0x02 0x06>;
					clock-names = "ipg_clk", "ipg_clk_app", "pll8k", "pll11k", "clkext3";
					dmas = <0x6f 0x18 0x19 0x80000000>;
					dma-names = "rx";
					power-domains = <0x70>;
					status = "disabled";
					phandle = <0x11b>;
				};

				aud2htx@30cb0000 {
					compatible = "fsl,imx8mp-aud2htx";
					reg = <0x30cb0000 0x10000>;
					interrupts = <0x00 0x82 0x04>;
					clocks = <0x47 0x21>;
					clock-names = "bus";
					dmas = <0x6f 0x1a 0x02 0x00>;
					dma-names = "tx";
					power-domains = <0x70>;
					status = "disabled";
					phandle = <0xa8>;
				};

				xcvr@30cc0000 {
					compatible = "fsl,imx8mp-xcvr";
					reg = <0x30cc0000 0x800 0x30cc0800 0x400 0x30cc0c00 0x80 0x30cc0e00 0x80>;
					reg-names = "ram", "regs", "rxfifo", "txfifo";
					interrupts = <0x00 0x80 0x04 0x00 0x81 0x04 0x00 0x92 0x04>;
					clocks = <0x47 0x1f 0x47 0x26 0x47 0x1c 0x47 0x23>;
					clock-names = "ipg", "phy", "spba", "pll_ipg";
					dmas = <0x6f 0x1e 0x02 0x00 0x6f 0x1f 0x02 0x00>;
					dma-names = "rx", "tx";
					resets = <0x47 0x00>;
					power-domains = <0x70>;
					status = "disabled";
					phandle = <0x11c>;
				};
			};

			dma-controller@30e00000 {
				compatible = "fsl,imx8mp-sdma", "fsl,imx7d-sdma";
				reg = <0x30e00000 0x10000>;
				interrupts = <0x00 0x22 0x04>;
				clocks = <0x47 0x1b 0x47 0x1b>;
				clock-names = "ipg", "ahb";
				#dma-cells = <0x03>;
				fsl,sdma-ram-script-name = "imx/sdma/sdma-imx7d.bin";
				fsl,ratio-1-1;
				power-domains = <0x70>;
				phandle = <0x11d>;
			};

			dma-controller@30e10000 {
				compatible = "fsl,imx8mp-sdma", "fsl,imx7d-sdma";
				reg = <0x30e10000 0x10000>;
				interrupts = <0x00 0x67 0x04>;
				clocks = <0x02 0x13b 0x02 0x13b>;
				clock-names = "ipg", "ahb";
				#dma-cells = <0x03>;
				fsl,sdma-ram-script-name = "imx/sdma/sdma-imx7d.bin";
				fsl,ratio-1-1;
				power-domains = <0x70>;
				phandle = <0x6f>;
			};

			audio-blk-ctrl@30e20000 {
				compatible = "fsl,imx8mp-audio-blk-ctrl", "syscon";
				reg = <0x30e20000 0x50c>;
				power-domains = <0x70>;
				#clock-cells = <0x01>;
				#reset-cells = <0x01>;
				assigned-clocks = <0x47 0x39>;
				assigned-clock-parents = <0x47 0x38>;
				phandle = <0x47>;
			};

			audiomix_dsp {
				compatible = "fsl,audiomix-dsp";
				power-domains = <0x70>;
				phandle = <0x11e>;
			};

			mu2@30e60000 {
				compatible = "fsl,imx8-mu-dsp", "fsl,imx6sx-mu";
				reg = <0x30e60000 0x10000>;
				interrupts = <0x00 0x88 0x04>;
				fsl,dsp_ap_mu_id = <0x02>;
				#mbox-cells = <0x02>;
				clocks = <0x47 0x24>;
				status = "okay";
				phandle = <0x11f>;
			};

			hdmi-blk-ctrl@32fc0000 {
				compatible = "fsl,imx8mp-hdmi-blk-ctrl", "syscon";
				reg = <0x32fc0000 0x1000>;
				power-domains = <0x0f>;
				#clock-cells = <0x01>;
				#reset-cells = <0x01>;
				phandle = <0x71>;
			};

			irqsteer@32fc2000 {
				compatible = "fsl,imx-irqsteer";
				reg = <0x32fc2000 0x1000>;
				interrupts = <0x00 0x2b 0x04>;
				interrupt-controller;
				#interrupt-cells = <0x01>;
				fsl,channel = <0x01>;
				fsl,num-irqs = <0x40>;
				clocks = <0x71 0x06>;
				clock-names = "ipg";
				assigned-clocks = <0x02 0x63>;
				assigned-clock-parents = <0x02 0x33>;
				assigned-clock-rates = <0x7ed6b40>;
				resets = <0x71 0x05>;
				status = "disabled";
				phandle = <0x73>;
			};

			hdmi-pai-pvi@32fc4000 {
				compatible = "fsl,imx8mp-hdmi-pavi";
				reg = <0x32fc4000 0x1000>;
				clocks = <0x71 0x20 0x71 0x17>;
				clock-names = "pvi_clk", "pai_clk";
				resets = <0x71 0x02 0x71 0x03>;
				reset-names = "pai_rst", "pvi_rst";
				status = "disabled";
				phandle = <0x120>;
			};

			lcd-controller@32fc6000 {
				#address-cells = <0x01>;
				#size-cells = <0x00>;
				compatible = "fsl,imx8mp-lcdif3";
				reg = <0x32fc6000 0x10000>;
				clocks = <0x72 0x00 0x02 0x64 0x02 0x63 0x71 0x00 0x71 0x01 0x71 0x03 0x71 0x05 0x71 0x09 0x71 0x0a 0x71 0x0b 0x71 0x0c 0x71 0x0d 0x71 0x07>;
				clock-names = "pix", "disp-axi", "disp-apb", "mix_apb", "mix_axi", "xtl_24m", "mix_pix", "lcdif_apb", "lcdif_axi", "lcdif_pdi", "lcdif_pix", "lcdif_spu", "noc_hdmi";
				assigned-clocks = <0x02 0x64 0x02 0x63>;
				assigned-clock-parents = <0x02 0x40 0x02 0x33>;
				assigned-clock-rates = <0x1dcd6500 0x7ed6b40>;
				interrupts = <0x08 0x04>;
				interrupt-parent = <0x73>;
				resets = <0x71 0x07>;
				fsl,gpr = <0x71>;
				power-domains = <0x0f>;
				status = "disabled";
				phandle = <0x121>;

				port@0 {
					reg = <0x00>;
					phandle = <0x0a>;

					endpoint {
						remote-endpoint = <0x74>;
						phandle = <0x76>;
					};
				};
			};

			hdmi@32fd8000 {
				compatible = "fsl,imx8mp-hdmi";
				reg = <0x32fd8000 0x7eff>;
				interrupts = <0x00 0x04>;
				interrupt-parent = <0x73>;
				clocks = <0x02 0x63 0x02 0xa7 0x71 0x1d 0x71 0x1b 0x71 0x1a 0x71 0x19 0x71 0x18 0x71 0x15 0x71 0x14 0x71 0x13 0x71 0x0e 0x71 0x24>;
				clock-names = "iahb", "isfr", "phy_int", "prep_clk", "skp_clk", "sfr_clk", "pix_clk", "cec_clk", "apb_clk", "hpi_clk", "fdcc_ref", "pipe_clk";
				assigned-clocks = <0x02 0x63 0x02 0x64 0x02 0xa7>;
				assigned-clock-parents = <0x02 0x33 0x02 0x40 0x02 0x02>;
				assigned-clock-rates = <0x7ed6b40 0x1dcd6500 0x16e3600>;
				phys = <0x72>;
				phy-names = "hdmi";
				resets = <0x71 0x00>;
				gpr = <0x71>;
				power-domains = <0x75>;
				status = "disabled";
				phandle = <0x122>;

				port@0 {

					endpoint {
						remote-endpoint = <0x76>;
						phandle = <0x74>;
					};
				};
			};

			hdmiphy@32fdff00 {
				compatible = "fsl,samsung-hdmi-phy";
				reg = <0x32fdff00 0x100>;
				#clock-cells = <0x01>;
				clocks = <0x71 0x1c 0x71 0x03>;
				clock-names = "apb", "ref";
				clock-output-names = "hdmi_phy";
				#phy-cells = <0x00>;
				resets = <0x71 0x01>;
				status = "disabled";
				phandle = <0x72>;
			};
		};

		interrupt-controller@38800000 {
			compatible = "arm,gic-v3";
			reg = <0x38800000 0x10000 0x38880000 0xc0000>;
			#interrupt-cells = <0x03>;
			interrupt-controller;
			interrupts = <0x01 0x09 0x04>;
			interrupt-parent = <0x01>;
			phandle = <0x01>;
		};

		dma-apbh@33000000 {
			compatible = "fsl,imx7d-dma-apbh", "fsl,imx28-dma-apbh";
			reg = <0x33000000 0x2000>;
			interrupts = <0x00 0x0c 0x04 0x00 0x0c 0x04 0x00 0x0c 0x04 0x00 0x0c 0x04>;
			interrupt-names = "gpmi0", "gpmi1", "gpmi2", "gpmi3";
			#dma-cells = <0x01>;
			dma-channels = <0x04>;
			clocks = <0x02 0xe4>;
			phandle = <0x77>;
		};

		gpmi-nand@33002000 {
			compatible = "fsl,imx7d-gpmi-nand";
			#address-cells = <0x01>;
			#size-cells = <0x01>;
			reg = <0x33002000 0x2000 0x33004000 0x4000>;
			reg-names = "gpmi-nand", "bch";
			interrupts = <0x00 0x0e 0x04>;
			interrupt-names = "bch";
			clocks = <0x02 0xe3 0x02 0xe4>;
			clock-names = "gpmi_io", "gpmi_bch_apb";
			dmas = <0x77 0x00>;
			dma-names = "rx-tx";
			status = "disabled";
			phandle = <0x123>;
		};

		pcie@33800000 {
			compatible = "fsl,imx8mp-pcie", "snps,dw-pcie";
			reg = <0x33800000 0x400000 0x1ff00000 0x80000>;
			reg-names = "dbi", "config";
			#address-cells = <0x03>;
			#size-cells = <0x02>;
			device_type = "pci";
			ranges = <0x81000000 0x00 0x00 0x1ff80000 0x00 0x10000 0x82000000 0x00 0x18000000 0x18000000 0x00 0x7f00000>;
			num-lanes = <0x01>;
			num-viewport = <0x04>;
			interrupts = <0x00 0x8c 0x04 0x00 0x7f 0x04>;
			interrupt-names = "msi";
			#interrupt-cells = <0x01>;
			interrupt-map-mask = <0x00 0x00 0x00 0x07>;
			interrupt-map = <0x00 0x00 0x00 0x01 0x01 0x00 0x7e 0x04 0x00 0x00 0x00 0x02 0x01 0x00 0x7d 0x04 0x00 0x00 0x00 0x03 0x01 0x00 0x7c 0x04 0x00 0x00 0x00 0x04 0x01 0x00 0x7b 0x04>;
			fsl,max-link-speed = <0x03>;
			linux,pci-domain = <0x00>;
			power-domains = <0x78>;
			resets = <0x79 0x18 0x79 0x19 0x79 0x1a 0x79 0x26 0x79 0x1b>;
			reset-names = "pciephy", "pciephy_perst", "apps", "clkreq", "turnoff";
			phys = <0x7a>;
			phy-names = "pcie-phy";
			fsl,imx8mp-hsio-mix = <0x7b>;
			status = "okay";
			assigned-clocks = <0x02 0x137 0x02 0x78>;
			assigned-clock-parents = <0x02 0x40 0x02 0x39>;
			assigned-clock-rates = <0x1dcd6500 0x989680>;
			bus-range = <0x00 0xff>;
			clocks = <0x02 0x10c 0x02 0x78 0x02 0x137 0x02 0xd9>;
			clock-names = "pcie", "pcie_aux", "pcie_phy", "pcie_bus";
			ext_osc = <0x00>;
			l1ss-disabled;
			pinctrl-names = "default";
			pinctrl-0 = <0x7c>;
			reset-gpio = <0x41 0x13 0x01>;
			epdev_on-supply = <0x40>;
			vpcie-supply = <0x7d>;
			phandle = <0x124>;
		};

		pcie_ep@33800000 {
			compatible = "fsl,imx8mp-pcie-ep";
			reg = <0x33800000 0x400000 0x18000000 0x8000000>;
			reg-names = "regs", "addr_space";
			num-lanes = <0x01>;
			interrupts = <0x00 0x7f 0x04>;
			interrupt-names = "dma";
			fsl,max-link-speed = <0x03>;
			power-domains = <0x78>;
			resets = <0x79 0x18 0x79 0x19 0x79 0x1a 0x79 0x26 0x79 0x1b>;
			reset-names = "pciephy", "pciephy_perst", "apps", "clkreq", "turnoff";
			phys = <0x7a>;
			phy-names = "pcie-phy";
			fsl,imx8mp-hsio-mix = <0x7b>;
			num-ib-windows = <0x04>;
			num-ob-windows = <0x04>;
			status = "disabled";
			phandle = <0x125>;
		};

		ddr-pmu@3d800000 {
			compatible = "fsl,imx8mp-ddr-pmu", "fsl,imx8m-ddr-pmu";
			reg = <0x3d800000 0x400000>;
			interrupts = <0x00 0x62 0x04>;
		};

		usb-phy@381f0040 {
			compatible = "fsl,imx8mp-usb-phy";
			reg = <0x381f0040 0x40>;
			clocks = <0x02 0x100>;
			clock-names = "phy";
			assigned-clocks = <0x02 0x93>;
			assigned-clock-parents = <0x02 0x02>;
			#phy-cells = <0x00>;
			status = "okay";
			phandle = <0x7f>;
		};

		usb@32f10100 {
			compatible = "fsl,imx8mp-dwc3";
			reg = <0x32f10100 0x08 0x381f0000 0x20>;
			clocks = <0x02 0x137 0x02 0x10c 0x02 0xff>;
			clock-names = "bus_early", "hsio", "suspend";
			interrupts = <0x00 0x94 0x04>;
			power-domains = <0x0b>;
			#address-cells = <0x01>;
			#size-cells = <0x01>;
			dma-ranges = <0x40000000 0x40000000 0xc0000000>;
			ranges;
			status = "okay";
			fsl,disable-port-power-control;
			fsl,over-current-active-low;
			pinctrl-names = "default";
			pinctrl-0 = <0x7e>;
			phandle = <0x126>;

			usb@38100000 {
				compatible = "snps,dwc3";
				reg = <0x38100000 0x10000>;
				clocks = <0x02 0x137 0x02 0x92 0x02 0xff>;
				clock-names = "bus_early", "ref", "suspend";
				assigned-clocks = <0x02 0x137>;
				assigned-clock-parents = <0x02 0x40>;
				assigned-clock-rates = <0x1dcd6500>;
				interrupts = <0x00 0x28 0x04>;
				phys = <0x7f 0x7f>;
				phy-names = "usb2-phy", "usb3-phy";
				snps,gfladj-refclk-lpm-sel-quirk;
				snps,parkmode-disable-ss-quirk;
				adp-disable;
				dr_mode = "otg";
				hnp-disable;
				maximum-speed = "high-speed";
				role-switch-default-mode = "peripheral";
				srp-disable;
				usb-role-switch;
				phandle = <0x127>;

				connector {
					compatible = "gpio-usb-b-connector", "usb-b-connector";
					id-gpios = <0x49 0x0a 0x00>;
					label = "Type-C";
					pinctrl-names = "default";
					pinctrl-0 = <0x80>;
					self-powered;
					type = "micro";
					vbus-supply = <0x81>;
				};
			};
		};

		usb-phy@382f0040 {
			compatible = "fsl,imx8mp-usb-phy";
			reg = <0x382f0040 0x40>;
			clocks = <0x02 0x100>;
			clock-names = "phy";
			assigned-clocks = <0x02 0x93>;
			assigned-clock-parents = <0x02 0x02>;
			#phy-cells = <0x00>;
			vbus-supply = <0x82>;
			status = "disabled";
			phandle = <0x83>;
		};

		usb@32f10108 {
			compatible = "fsl,imx8mp-dwc3";
			reg = <0x32f10108 0x08 0x382f0000 0x20>;
			clocks = <0x02 0x137 0x02 0x10c 0x02 0xff>;
			clock-names = "bus_early", "hsio", "suspend";
			interrupts = <0x00 0x95 0x04>;
			power-domains = <0x0b>;
			#address-cells = <0x01>;
			#size-cells = <0x01>;
			dma-ranges = <0x40000000 0x40000000 0xc0000000>;
			ranges;
			status = "disabled";
			fsl,disable-port-power-control;
			fsl,permanently-attached;
			phandle = <0x128>;

			usb@38200000 {
				compatible = "snps,dwc3";
				reg = <0x38200000 0x10000>;
				clocks = <0x02 0x137 0x02 0x92 0x02 0xff>;
				clock-names = "bus_early", "ref", "suspend";
				assigned-clocks = <0x02 0x137>;
				assigned-clock-parents = <0x02 0x40>;
				assigned-clock-rates = <0x1dcd6500>;
				interrupts = <0x00 0x29 0x04>;
				phys = <0x83 0x83>;
				phy-names = "usb2-phy", "usb3-phy";
				snps,gfladj-refclk-lpm-sel-quirk;
				snps,parkmode-disable-ss-quirk;
				dr_mode = "host";
				#address-cells = <0x01>;
				#size-cells = <0x00>;
				phandle = <0x129>;

				usb-hub@1 {
					compatible = "usb424,5744";
					reg = <0x01>;
					peer-hub = <0x84>;
					vdd-supply = <0x85>;
					phandle = <0x86>;
				};

				usb-hub@2 {
					compatible = "usb424,2744";
					reg = <0x02>;
					peer-hub = <0x86>;
					vdd-supply = <0x85>;
					phandle = <0x84>;
				};
			};
		};

		memory-controller@3d400000 {
			compatible = "fsl,imx8mp-ddrc";
			reg = <0x3d400000 0x400000>;
			interrupts = <0x00 0x93 0x04>;
			phandle = <0x12a>;
		};
	};

	vpu_g1@38300000 {
		compatible = "nxp,imx8mm-hantro", "nxp,imx8mp-hantro";
		reg = <0x00 0x38300000 0x00 0x100000>;
		reg-names = "regs_hantro";
		interrupts = <0x00 0x07 0x04>;
		interrupt-names = "irq_hantro";
		clocks = <0x02 0x106 0x02 0x11a>;
		clock-names = "clk_hantro", "clk_hantro_bus";
		assigned-clocks = <0x02 0x72 0x02 0x60>;
		assigned-clock-parents = <0x02 0x38 0x02 0x38>;
		assigned-clock-rates = <0x2faf0800 0x2faf0800>;
		power-domains = <0x87>;
		status = "okay";
		phandle = <0x12b>;
	};

	vpu_g2@38310000 {
		compatible = "nxp,imx8mm-hantro", "nxp,imx8mp-hantro";
		reg = <0x00 0x38310000 0x00 0x100000>;
		reg-names = "regs_hantro";
		interrupts = <0x00 0x08 0x04>;
		interrupt-names = "irq_hantro";
		clocks = <0x02 0x10a 0x02 0x11a>;
		clock-names = "clk_hantro", "clk_hantro_bus";
		assigned-clocks = <0x02 0x73 0x02 0x60 0x02 0x17>;
		assigned-clock-parents = <0x02 0x2b 0x02 0x38>;
		assigned-clock-rates = <0x29b92700 0x2faf0800 0x29b92700>;
		power-domains = <0x88>;
		status = "okay";
		phandle = <0x12c>;
	};

	vpu_vc8000e@38320000 {
		compatible = "nxp,imx8mp-hantro-vc8000e";
		reg = <0x00 0x38320000 0x00 0x10000>;
		reg-names = "regs_hantro_vc8000e";
		interrupts = <0x00 0x1e 0x04>;
		interrupt-names = "irq_hantro_vc8000e";
		clocks = <0x02 0x109 0x02 0x11a>;
		clock-names = "clk_hantro_vc8000e", "clk_hantro_vc8000e_bus";
		assigned-clocks = <0x02 0xb5 0x02 0x60>;
		assigned-clock-parents = <0x02 0x41 0x02 0x38>;
		assigned-clock-rates = <0x1dcd6500 0x2faf0800>;
		power-domains = <0x89>;
		status = "okay";
		phandle = <0x12d>;
	};

	vpu_v4l2 {
		compatible = "nxp,imx8m-vsiv4l2";
		status = "okay";
		phandle = <0x12e>;
	};

	gpu3d@38000000 {
		compatible = "fsl,imx8-gpu";
		reg = <0x00 0x38000000 0x00 0x8000>;
		interrupts = <0x00 0x03 0x04>;
		clocks = <0x02 0xf8 0x02 0x134 0x02 0x65 0x02 0x66>;
		clock-names = "core", "shader", "axi", "ahb";
		assigned-clocks = <0x02 0x133 0x02 0x134 0x02 0x65 0x02 0x66>;
		assigned-clock-parents = <0x02 0x41 0x02 0x41 0x02 0x38 0x02 0x38>;
		assigned-clock-rates = <0x3b9aca00 0x3b9aca00 0x2faf0800 0x17d78400>;
		power-domains = <0x8a>;
		status = "disabled";
		phandle = <0x8d>;
	};

	gpu2d@38008000 {
		compatible = "fsl,imx8-gpu";
		reg = <0x00 0x38008000 0x00 0x8000>;
		interrupts = <0x00 0x19 0x04>;
		clocks = <0x02 0xf7 0x02 0x65 0x02 0x66>;
		clock-names = "core", "axi", "ahb";
		assigned-clocks = <0x02 0x135 0x02 0x65 0x02 0x66>;
		assigned-clock-parents = <0x02 0x41 0x02 0x38 0x02 0x38>;
		assigned-clock-rates = <0x3b9aca00 0x2faf0800 0x17d78400>;
		power-domains = <0x8b>;
		status = "disabled";
		phandle = <0x8f>;
	};

	vipsi@38500000 {
		compatible = "fsl,imx8-gpu", "fsl,imx8-vipsi";
		reg = <0x00 0x38500000 0x00 0x20000>;
		interrupts = <0x00 0x0d 0x04>;
		clocks = <0x02 0x10b 0x02 0x10b 0x02 0x69 0x02 0x6a>;
		clock-names = "core", "shader", "axi", "ahb";
		assigned-clocks = <0x02 0x132 0x02 0x69 0x02 0x6a>;
		assigned-clock-parents = <0x02 0x41 0x02 0x38 0x02 0x38>;
		assigned-clock-rates = <0x3b9aca00 0x2faf0800 0x17d78400>;
		power-domains = <0x8c>;
		status = "disabled";
		phandle = <0x8e>;
	};

	mix_gpu_ml {
		compatible = "fsl,imx8mp-gpu", "fsl,imx8-gpu-ss";
		cores = <0x8d 0x8e 0x8f>;
		reg = <0x00 0x40000000 0x00 0xc0000000 0x00 0x00 0x00 0x10000000>;
		reg-names = "phys_baseaddr", "contiguous_mem";
		status = "disabled";
		phandle = <0x12f>;
	};

	i2c-rpbus-3 {
		compatible = "fsl,i2c-rpbus";
		status = "disabled";
		phandle = <0x130>;
	};

	etm@28440000 {
		compatible = "arm,coresight-etm4x", "arm,primecell";
		reg = <0x00 0x28440000 0x00 0x10000>;
		arm,primecell-periphid = <0xbb95d>;
		cpu = <0x12>;
		clocks = <0x02 0x5d>;
		clock-names = "apb_pclk";
		status = "disabled";
		phandle = <0x131>;

		out-ports {

			port {

				endpoint {
					remote-endpoint = <0x90>;
					phandle = <0x94>;
				};
			};
		};
	};

	etm@28540000 {
		compatible = "arm,coresight-etm4x", "arm,primecell";
		reg = <0x00 0x28540000 0x00 0x10000>;
		arm,primecell-periphid = <0xbb95d>;
		cpu = <0x13>;
		clocks = <0x02 0x5d>;
		clock-names = "apb_pclk";
		status = "disabled";
		phandle = <0x132>;

		out-ports {

			port {

				endpoint {
					remote-endpoint = <0x91>;
					phandle = <0x95>;
				};
			};
		};
	};

	etm@28640000 {
		compatible = "arm,coresight-etm4x", "arm,primecell";
		reg = <0x00 0x28640000 0x00 0x10000>;
		arm,primecell-periphid = <0xbb95d>;
		cpu = <0x14>;
		clocks = <0x02 0x5d>;
		clock-names = "apb_pclk";
		status = "disabled";
		phandle = <0x133>;

		out-ports {

			port {

				endpoint {
					remote-endpoint = <0x92>;
					phandle = <0x96>;
				};
			};
		};
	};

	etm@28740000 {
		compatible = "arm,coresight-etm4x", "arm,primecell";
		reg = <0x00 0x28740000 0x00 0x10000>;
		arm,primecell-periphid = <0xbb95d>;
		cpu = <0x15>;
		clocks = <0x02 0x5d>;
		clock-names = "apb_pclk";
		status = "disabled";
		phandle = <0x134>;

		out-ports {

			port {

				endpoint {
					remote-endpoint = <0x93>;
					phandle = <0x97>;
				};
			};
		};
	};

	funnel {
		compatible = "arm,coresight-static-funnel";
		status = "disabled";
		phandle = <0x135>;

		in-ports {
			#address-cells = <0x01>;
			#size-cells = <0x00>;

			port@0 {
				reg = <0x00>;

				endpoint {
					remote-endpoint = <0x94>;
					phandle = <0x90>;
				};
			};

			port@1 {
				reg = <0x01>;

				endpoint {
					remote-endpoint = <0x95>;
					phandle = <0x91>;
				};
			};

			port@2 {
				reg = <0x02>;

				endpoint {
					remote-endpoint = <0x96>;
					phandle = <0x92>;
				};
			};

			port@3 {
				reg = <0x03>;

				endpoint {
					remote-endpoint = <0x97>;
					phandle = <0x93>;
				};
			};
		};

		out-ports {

			port {

				endpoint {
					remote-endpoint = <0x98>;
					phandle = <0x99>;
				};
			};
		};
	};

	funnel@28c03000 {
		compatible = "arm,coresight-dynamic-funnel", "arm,primecell";
		reg = <0x00 0x28c03000 0x00 0x1000>;
		clocks = <0x02 0x5d>;
		clock-names = "apb_pclk";
		status = "disabled";
		phandle = <0x136>;

		in-ports {
			#address-cells = <0x01>;
			#size-cells = <0x00>;

			port@0 {
				reg = <0x00>;

				endpoint {
					remote-endpoint = <0x99>;
					phandle = <0x98>;
				};
			};

			port@1 {
				reg = <0x01>;

				endpoint {
					phandle = <0x137>;
				};
			};

			port@2 {
				reg = <0x02>;

				endpoint {
					phandle = <0x138>;
				};
			};
		};

		out-ports {

			port {

				endpoint {
					remote-endpoint = <0x9a>;
					phandle = <0x9b>;
				};
			};
		};
	};

	etf@28c04000 {
		compatible = "arm,coresight-tmc", "arm,primecell";
		reg = <0x00 0x28c04000 0x00 0x1000>;
		clocks = <0x02 0x5d>;
		clock-names = "apb_pclk";
		status = "disabled";

		in-ports {

			port {

				endpoint {
					remote-endpoint = <0x9b>;
					phandle = <0x9a>;
				};
			};
		};

		out-ports {

			port {

				endpoint {
					remote-endpoint = <0x9c>;
					phandle = <0x9d>;
				};
			};
		};
	};

	etr@28c06000 {
		compatible = "arm,coresight-tmc", "arm,primecell";
		reg = <0x00 0x28c06000 0x00 0x1000>;
		clocks = <0x02 0x5d>;
		clock-names = "apb_pclk";
		status = "disabled";

		in-ports {

			port {

				endpoint {
					remote-endpoint = <0x9d>;
					phandle = <0x9c>;
				};
			};
		};
	};

	chosen {
		stdout-path = "/soc@0/bus@30800000/serial@30880000";
	};

	backlight {
		compatible = "pwm-backlight";
		brightness-levels = <0x00 0x2d 0x3f 0x58 0x77 0x9e 0xcb 0xff>;
		default-brightness-level = <0x04>;
		enable-gpios = <0x37 0x01 0x00>;
		pinctrl-names = "default";
		pinctrl-0 = <0x9e>;
		power-supply = <0x40>;
		pwms = <0x9f 0x00 0x65b9ab 0x01>;
		status = "disabled";
		phandle = <0xa5>;
	};

	backlight-mezzanine {
		compatible = "pwm-backlight";
		brightness-levels = <0x00 0x2d 0x3f 0x58 0x77 0x9e 0xcb 0xff>;
		default-brightness-level = <0x04>;
		enable-gpios = <0x2d 0x06 0x00>;
		pwms = <0xa0 0x00 0x65b9ab 0x01>;
		status = "disabled";
		phandle = <0xa6>;
	};

	gpio-keys {
		compatible = "gpio-keys";
		pinctrl-names = "default";
		pinctrl-0 = <0xa1>;

		button-wakeup {
			debounce-interval = <0x0a>;
			gpios = <0x41 0x00 0x01>;
			label = "Wake-Up";
			linux,code = <0x8f>;
			wakeup-source;
		};
	};

	hdmi-connector {
		compatible = "hdmi-connector";
		ddc-i2c-bus = <0xa2>;
		hpd-gpios = <0xa3 0x14 0x00>;
		label = "hdmi";
		pinctrl-names = "default";
		pinctrl-0 = <0xa4>;
		type = "a";
		status = "disabled";
		phandle = <0x139>;
	};

	panel-lvds {
		compatible = "panel-lvds";
		backlight = <0xa5>;
		data-mapping = "vesa-24";
		status = "disabled";
		phandle = <0x13a>;
	};

	panel-lvds-mez {
		compatible = "panel-lvds";
		backlight = <0xa6>;
		data-mapping = "vesa-24";
		status = "disabled";
		phandle = <0x13b>;

		port {

			endpoint {
				remote-endpoint = <0xa7>;
				phandle = <0x67>;
			};
		};
	};

	sound-hdmi {
		compatible = "fsl,imx-audio-hdmi";
		model = "audio-hdmi";
		audio-cpu = <0xa8>;
		hdmi-out;
		constraint-rate = <0xac44 0x15888 0x2b110 0x7d00 0xbb80 0x17700 0x2ee00>;
		status = "disabled";
		phandle = <0x13c>;
	};

	regulator-1p8v {
		compatible = "regulator-fixed";
		regulator-always-on;
		regulator-max-microvolt = <0x1b7740>;
		regulator-min-microvolt = <0x1b7740>;
		regulator-name = "+V1.8_SW";
		phandle = <0x45>;
	};

	regulator-3p3v {
		compatible = "regulator-fixed";
		regulator-always-on;
		regulator-max-microvolt = <0x325aa0>;
		regulator-min-microvolt = <0x325aa0>;
		regulator-name = "+V3.3_SW";
		phandle = <0x40>;
	};

	regulator-5p0v {
		compatible = "regulator-fixed";
		regulator-always-on;
		regulator-max-microvolt = <0x4c4b40>;
		regulator-min-microvolt = <0x4c4b40>;
		regulator-name = "+V5_SW";
		phandle = <0x13d>;
	};

	regulator-module-eth1phy {
		compatible = "regulator-fixed";
		enable-active-high;
		gpio = <0x49 0x14 0x00>;
		off-on-delay = <0x7a120>;
		pinctrl-names = "default";
		pinctrl-0 = <0xa9>;
		regulator-always-on;
		regulator-boot-on;
		regulator-max-microvolt = <0x325aa0>;
		regulator-min-microvolt = <0x325aa0>;
		regulator-name = "On-module +V3.3_ETH";
		startup-delay-us = <0x30d40>;
		vin-supply = <0xaa>;
		phandle = <0x5b>;
	};

	regulator-force-sleep-moci {
		compatible = "regulator-fixed";
		enable-active-high;
		gpio = <0x41 0x1d 0x00>;
		regulator-always-on;
		regulator-boot-on;
		regulator-name = "CTRL_SLEEP_MOCI#";
		status = "disabled";
		phandle = <0x13e>;
	};

	regulator-usb1-vbus {
		compatible = "regulator-fixed";
		enable-active-high;
		gpio = <0x2d 0x0c 0x00>;
		pinctrl-names = "default";
		pinctrl-0 = <0xab>;
		regulator-max-microvolt = <0x4c4b40>;
		regulator-min-microvolt = <0x4c4b40>;
		regulator-name = "USB_1_EN";
		phandle = <0x81>;
	};

	regulator-usb2-vbus {
		compatible = "regulator-fixed";
		enable-active-high;
		gpio = <0x2d 0x0e 0x00>;
		pinctrl-names = "default";
		pinctrl-0 = <0xac>;
		regulator-max-microvolt = <0x4c4b40>;
		regulator-min-microvolt = <0x4c4b40>;
		regulator-name = "USB_2_EN";
		phandle = <0x82>;
	};

	regulator-usdhc2 {
		compatible = "regulator-fixed";
		enable-active-high;
		gpio = <0x41 0x16 0x00>;
		off-on-delay = <0x186a0>;
		pinctrl-names = "default";
		pinctrl-0 = <0xad>;
		regulator-max-microvolt = <0x325aa0>;
		regulator-min-microvolt = <0x325aa0>;
		regulator-name = "+V3.3_SD";
		startup-delay-us = <0x4e20>;
		vin-supply = <0x40>;
		phandle = <0x50>;
	};

	sound {
		compatible = "simple-audio-card";
		simple-audio-card,bitclock-master = <0xae>;
		simple-audio-card,format = "i2s";
		simple-audio-card,frame-master = <0xae>;
		simple-audio-card,mclk-fs = <0x100>;
		simple-audio-card,name = "verdin-wm8904";
		simple-audio-card,routing = "Headphone Jack", "HPOUTL", "Headphone Jack", "HPOUTR", "IN2L", "Line In Jack", "IN2R", "Line In Jack", "Headphone Jack", "MICBIAS", "IN1L", "Headphone Jack";
		simple-audio-card,widgets = "Microphone", "Headphone Jack", "Headphone", "Headphone Jack", "Line", "Line In Jack";

		simple-audio-card,codec {
			clocks = <0x47 0x01>;
			sound-dai = <0xaf>;
			phandle = <0xae>;
		};

		simple-audio-card,cpu {
			sound-dai = <0xb0>;
		};
	};

	regulator-usb-hub {
		compatible = "regulator-fixed";
		enable-active-high;
		gpio = <0x41 0x1d 0x00>;
		regulator-boot-on;
		regulator-name = "HUB_PWR_EN";
		phandle = <0x85>;
	};

	regulator-pcie {
		compatible = "regulator-fixed";
		enable-active-high;
		gpio = <0x41 0x1d 0x00>;
		regulator-boot-on;
		regulator-name = "PCIE_1_PWR_EN";
		startup-delay-us = <0x186a0>;
		phandle = <0x7d>;
	};

	__symbols__ {
		cpu_pd_wait = "/cpus/idle-states/cpu-pd-wait";
		A53_0 = "/cpus/cpu@0";
		A53_1 = "/cpus/cpu@1";
		A53_2 = "/cpus/cpu@2";
		A53_3 = "/cpus/cpu@3";
		A53_L2 = "/cpus/l2-cache0";
		a53_opp_table = "/opp-table";
		resmem = "/reserved-memory";
		ocram = "/reserved-memory/ocram@900000";
		osc_32k = "/clock-osc-32k";
		osc_24m = "/clock-osc-24m";
		clk_ext1 = "/clock-ext1";
		clk_ext2 = "/clock-ext2";
		clk_ext3 = "/clock-ext3";
		clk_ext4 = "/clock-ext4";
		sai1_mclk = "/sai-mclk1";
		sai2_mclk = "/sai-mclk2";
		sai3_mclk = "/sai-mclk3";
		sai5_mclk = "/sai-mclk5";
		sai6_mclk = "/sai-mclk6";
		sai7_mclk = "/sai-mclk7";
		hsiomix_pd = "/power-domains/hsiomix-pd";
		pcie_pd = "/power-domains/pcie-pd";
		usb_otg1_pd = "/power-domains/usbotg1-pd";
		usb_otg2_pd = "/power-domains/usbotg2-pd";
		mlmix_pd = "/power-domains/mlmix-pd";
		audiomix_pd = "/power-domains/audiomix-pd";
		gpumix_pd = "/power-domains/gpumix-pd";
		gpu2d_pd = "/power-domains/gpu2d-pd";
		gpu3d_pd = "/power-domains/gpu3d-pd";
		vpumix_pd = "/power-domains/vpumix-pd";
		vpu_g1_pd = "/power-domains/vpug1-pd";
		vpu_g2_pd = "/power-domains/vpug2-pd";
		vpu_h1_pd = "/power-domains/vpuh1-pd";
		mediamix_pd = "/power-domains/mediamix-pd";
		ispdwp_pd = "/power-domains/power-domain@14";
		mipi_phy1_pd = "/power-domains/mipiphy1-pd";
		mipi_phy2_pd = "/power-domains/mipiphy2-pd";
		hdmimix_pd = "/power-domains/hdmimix-pd";
		hdmi_phy_pd = "/power-domains/hdmiphy-pd";
		cpu_alert0 = "/thermal-zones/cpu-thermal/trips/trip0";
		cpu_crit0 = "/thermal-zones/cpu-thermal/trips/trip1";
		soc_alert0 = "/thermal-zones/soc-thermal/trips/trip0";
		soc_crit0 = "/thermal-zones/soc-thermal/trips/trip1";
		clk_dummy = "/clock-dummy";
		caam_sm = "/soc@0/caam-sm@100000";
		aips1 = "/soc@0/bus@30000000";
		gpio1 = "/soc@0/bus@30000000/gpio@30200000";
		gpio2 = "/soc@0/bus@30000000/gpio@30210000";
		gpio3 = "/soc@0/bus@30000000/gpio@30220000";
		gpio4 = "/soc@0/bus@30000000/gpio@30230000";
		gpio5 = "/soc@0/bus@30000000/gpio@30240000";
		tmu = "/soc@0/bus@30000000/tmu@30260000";
		wdog1 = "/soc@0/bus@30000000/watchdog@30280000";
		wdog2 = "/soc@0/bus@30000000/watchdog@30290000";
		wdog3 = "/soc@0/bus@30000000/watchdog@302a0000";
		iomuxc = "/soc@0/bus@30000000/pinctrl@30330000";
		pinctrl_bt_uart = "/soc@0/bus@30000000/pinctrl@30330000/btuartgrp";
		pinctrl_ctrl_sleep_moci = "/soc@0/bus@30000000/pinctrl@30330000/ctrlsleepmocigrp";
		pinctrl_ecspi1 = "/soc@0/bus@30000000/pinctrl@30330000/ecspi1grp";
		pinctrl_eqos = "/soc@0/bus@30000000/pinctrl@30330000/eqosgrp";
		pinctrl_eth_tpm_int = "/soc@0/bus@30000000/pinctrl@30330000/ethtpmintgrp";
		pinctrl_fec = "/soc@0/bus@30000000/pinctrl@30330000/fecgrp";
		pinctrl_fec_sleep = "/soc@0/bus@30000000/pinctrl@30330000/fecsleepgrp";
		pinctrl_flexcan1 = "/soc@0/bus@30000000/pinctrl@30330000/flexcan1grp";
		pinctrl_flexcan2 = "/soc@0/bus@30000000/pinctrl@30330000/flexcan2grp";
		pinctrl_flexspi0 = "/soc@0/bus@30000000/pinctrl@30330000/flexspi0grp";
		pinctrl_gpio1 = "/soc@0/bus@30000000/pinctrl@30330000/gpio1grp";
		pinctrl_gpio2 = "/soc@0/bus@30000000/pinctrl@30330000/gpio2grp";
		pinctrl_gpio3 = "/soc@0/bus@30000000/pinctrl@30330000/gpio3grp";
		pinctrl_gpio4 = "/soc@0/bus@30000000/pinctrl@30330000/gpio4grp";
		pinctrl_gpio5 = "/soc@0/bus@30000000/pinctrl@30330000/gpio5grp";
		pinctrl_gpio6 = "/soc@0/bus@30000000/pinctrl@30330000/gpio6grp";
		pinctrl_gpio7 = "/soc@0/bus@30000000/pinctrl@30330000/gpio7grp";
		pinctrl_gpio8 = "/soc@0/bus@30000000/pinctrl@30330000/gpio8grp";
		pinctrl_gpio_9_dsi = "/soc@0/bus@30000000/pinctrl@30330000/gpio9dsigrp";
		pinctrl_gpio_10_dsi = "/soc@0/bus@30000000/pinctrl@30330000/gpio10dsigrp";
		pinctrl_gpio_hog1 = "/soc@0/bus@30000000/pinctrl@30330000/gpiohog1grp";
		pinctrl_gpio_hog2 = "/soc@0/bus@30000000/pinctrl@30330000/gpiohog2grp";
		pinctrl_gpio_hog3 = "/soc@0/bus@30000000/pinctrl@30330000/gpiohog3grp";
		pinctrl_gpio_hog4 = "/soc@0/bus@30000000/pinctrl@30330000/gpiohog4grp";
		pinctrl_gpio_keys = "/soc@0/bus@30000000/pinctrl@30330000/gpiokeysgrp";
		pinctrl_hdmi_hog = "/soc@0/bus@30000000/pinctrl@30330000/hdmihoggrp";
		pinctrl_i2c1 = "/soc@0/bus@30000000/pinctrl@30330000/i2c1grp";
		pinctrl_i2c1_gpio = "/soc@0/bus@30000000/pinctrl@30330000/i2c1gpiogrp";
		pinctrl_i2c2 = "/soc@0/bus@30000000/pinctrl@30330000/i2c2grp";
		pinctrl_i2c2_gpio = "/soc@0/bus@30000000/pinctrl@30330000/i2c2gpiogrp";
		pinctrl_i2c3 = "/soc@0/bus@30000000/pinctrl@30330000/i2c3grp";
		pinctrl_i2c3_gpio = "/soc@0/bus@30000000/pinctrl@30330000/i2c3gpiogrp";
		pinctrl_i2c4 = "/soc@0/bus@30000000/pinctrl@30330000/i2c4grp";
		pinctrl_i2c4_gpio = "/soc@0/bus@30000000/pinctrl@30330000/i2c4gpiogrp";
		pinctrl_i2s_2_bclk_touch_reset = "/soc@0/bus@30000000/pinctrl@30330000/i2s2bclktouchresetgrp";
		pinctrl_i2s_2_d_out_dsi_1_bkl_en = "/soc@0/bus@30000000/pinctrl@30330000/i2s2doutdsi1bklengrp";
		pinctrl_pcie = "/soc@0/bus@30000000/pinctrl@30330000/pciegrp";
		pinctrl_pmic = "/soc@0/bus@30000000/pinctrl@30330000/pmicirqgrp";
		pinctrl_pwm_1 = "/soc@0/bus@30000000/pinctrl@30330000/pwm1grp";
		pinctrl_pwm_2 = "/soc@0/bus@30000000/pinctrl@30330000/pwm2grp";
		pinctrl_pwm_3 = "/soc@0/bus@30000000/pinctrl@30330000/pwm3grp";
		pinctrl_pwm_3_dsi_hpd_gpio = "/soc@0/bus@30000000/pinctrl@30330000/pwm3dsi1hpdgpiogrp";
		pinctrl_reg_eth = "/soc@0/bus@30000000/pinctrl@30330000/regethgrp";
		pinctrl_sai1 = "/soc@0/bus@30000000/pinctrl@30330000/sai1grp";
		pinctrl_sai3 = "/soc@0/bus@30000000/pinctrl@30330000/sai3grp";
		pinctrl_uart1 = "/soc@0/bus@30000000/pinctrl@30330000/uart1grp";
		pinctrl_uart2 = "/soc@0/bus@30000000/pinctrl@30330000/uart2grp";
		pinctrl_uart3 = "/soc@0/bus@30000000/pinctrl@30330000/uart3grp";
		pinctrl_uart4 = "/soc@0/bus@30000000/pinctrl@30330000/uart4grp";
		pinctrl_usb1_vbus = "/soc@0/bus@30000000/pinctrl@30330000/usb1vbusgrp";
		pinctrl_usb_1_id = "/soc@0/bus@30000000/pinctrl@30330000/usb1idgrp";
		pinctrl_usb_1_oc_n = "/soc@0/bus@30000000/pinctrl@30330000/usb1ocngrp";
		pinctrl_usb2_vbus = "/soc@0/bus@30000000/pinctrl@30330000/usb2vbusgrp";
		pinctrl_usdhc1 = "/soc@0/bus@30000000/pinctrl@30330000/usdhc1grp";
		pinctrl_usdhc1_100mhz = "/soc@0/bus@30000000/pinctrl@30330000/usdhc1-100mhzgrp";
		pinctrl_usdhc1_200mhz = "/soc@0/bus@30000000/pinctrl@30330000/usdhc1-200mhzgrp";
		pinctrl_usdhc2_cd = "/soc@0/bus@30000000/pinctrl@30330000/usdhc2cdgrp";
		pinctrl_usdhc2_cd_sleep = "/soc@0/bus@30000000/pinctrl@30330000/usdhc2cdslpgrp";
		pinctrl_usdhc2_pwr_en = "/soc@0/bus@30000000/pinctrl@30330000/usdhc2pwrengrp";
		pinctrl_usdhc2 = "/soc@0/bus@30000000/pinctrl@30330000/usdhc2grp";
		pinctrl_usdhc2_100mhz = "/soc@0/bus@30000000/pinctrl@30330000/usdhc2-100mhzgrp";
		pinctrl_usdhc2_200mhz = "/soc@0/bus@30000000/pinctrl@30330000/usdhc2-200mhzgrp";
		pinctrl_usdhc2_sleep = "/soc@0/bus@30000000/pinctrl@30330000/usdhc2slpgrp";
		pinctrl_usdhc3 = "/soc@0/bus@30000000/pinctrl@30330000/usdhc3grp";
		pinctrl_usdhc3_100mhz = "/soc@0/bus@30000000/pinctrl@30330000/usdhc3-100mhzgrp";
		pinctrl_usdhc3_200mhz = "/soc@0/bus@30000000/pinctrl@30330000/usdhc3-200mhzgrp";
		pinctrl_wdog = "/soc@0/bus@30000000/pinctrl@30330000/wdoggrp";
		pinctrl_bluetooth_ctrl = "/soc@0/bus@30000000/pinctrl@30330000/bluetoothctrlgrp";
		pinctrl_wifi_ctrl = "/soc@0/bus@30000000/pinctrl@30330000/wifictrlgrp";
		pinctrl_wifi_i2s = "/soc@0/bus@30000000/pinctrl@30330000/wifii2sgrp";
		pinctrl_wifi_pwr_en = "/soc@0/bus@30000000/pinctrl@30330000/wifipwrengrp";
		gpr = "/soc@0/bus@30000000/iomuxc-gpr@30340000";
		ocotp = "/soc@0/bus@30000000/efuse@30350000";
		imx8mp_uid = "/soc@0/bus@30000000/efuse@30350000/unique-id@8";
		cpu_speed_grade = "/soc@0/bus@30000000/efuse@30350000/speed-grade@10";
		eth_mac1 = "/soc@0/bus@30000000/efuse@30350000/mac-address@90";
		eth_mac2 = "/soc@0/bus@30000000/efuse@30350000/mac-address@650";
		imx8mp_soc = "/soc@0/bus@30000000/efuse@30350000/imx8mp-soc";
		anatop = "/soc@0/bus@30000000/anatop@30360000";
		irq_sec_vio = "/soc@0/bus@30000000/caam_secvio";
		caam_snvs = "/soc@0/bus@30000000/caam-snvs@30370000";
		snvs = "/soc@0/bus@30000000/snvs@30370000";
		snvs_rtc = "/soc@0/bus@30000000/snvs@30370000/snvs-rtc-lp";
		snvs_pwrkey = "/soc@0/bus@30000000/snvs@30370000/snvs-powerkey";
		clk = "/soc@0/bus@30000000/clock-controller@30380000";
		src = "/soc@0/bus@30000000/reset-controller@30390000";
		aips2 = "/soc@0/bus@30400000";
		pwm1 = "/soc@0/bus@30400000/pwm@30660000";
		pwm2 = "/soc@0/bus@30400000/pwm@30670000";
		pwm3 = "/soc@0/bus@30400000/pwm@30680000";
		pwm4 = "/soc@0/bus@30400000/pwm@30690000";
		system_counter = "/soc@0/bus@30400000/timer@306a0000";
		aips3 = "/soc@0/bus@30800000";
		ecspi1 = "/soc@0/bus@30800000/spi@30820000";
		ecspi2 = "/soc@0/bus@30800000/spi@30830000";
		ecspi3 = "/soc@0/bus@30800000/spi@30840000";
		uart1 = "/soc@0/bus@30800000/serial@30860000";
		uart3 = "/soc@0/bus@30800000/serial@30880000";
		uart2 = "/soc@0/bus@30800000/serial@30890000";
		flexcan1 = "/soc@0/bus@30800000/can@308c0000";
		flexcan2 = "/soc@0/bus@30800000/can@308d0000";
		crypto = "/soc@0/bus@30800000/crypto@30900000";
		sec_jr0 = "/soc@0/bus@30800000/crypto@30900000/jr@1000";
		sec_jr1 = "/soc@0/bus@30800000/crypto@30900000/jr@2000";
		sec_jr2 = "/soc@0/bus@30800000/crypto@30900000/jr@3000";
		i2c1 = "/soc@0/bus@30800000/i2c@30a20000";
		pca9450 = "/soc@0/bus@30800000/i2c@30a20000/pmic@25";
		reg_vdd_arm = "/soc@0/bus@30800000/i2c@30a20000/pmic@25/regulators/BUCK2";
		reg_vdd_3v3 = "/soc@0/bus@30800000/i2c@30a20000/pmic@25/regulators/BUCK4";
		reg_vdd_1v8 = "/soc@0/bus@30800000/i2c@30a20000/pmic@25/regulators/BUCK5";
		rtc_i2c = "/soc@0/bus@30800000/i2c@30a20000/rtc@32";
		hwmon_temp_module = "/soc@0/bus@30800000/i2c@30a20000/sensor@48";
		i2c2 = "/soc@0/bus@30800000/i2c@30a30000";
		atmel_mxt_ts_mezzanine = "/soc@0/bus@30800000/i2c@30a30000/touch-mezzanine@4a";
		i2c3 = "/soc@0/bus@30800000/i2c@30a40000";
		i2c4 = "/soc@0/bus@30800000/i2c@30a50000";
		gpio_expander_21 = "/soc@0/bus@30800000/i2c@30a50000/gpio-expander@21";
		lvds_ti_sn65dsi84 = "/soc@0/bus@30800000/i2c@30a50000/bridge@2c";
		hwmon = "/soc@0/bus@30800000/i2c@30a50000/hwmon@40";
		hdmi_lontium_lt8912 = "/soc@0/bus@30800000/i2c@30a50000/hdmi@48";
		atmel_mxt_ts = "/soc@0/bus@30800000/i2c@30a50000/touch@4a";
		hwmon_temp = "/soc@0/bus@30800000/i2c@30a50000/sensor@4f";
		eeprom_display_adapter = "/soc@0/bus@30800000/i2c@30a50000/eeprom@50";
		eeprom_carrier_board = "/soc@0/bus@30800000/i2c@30a50000/eeprom@57";
		wm8904_1a = "/soc@0/bus@30800000/i2c@30a50000/audio-codec@1a";
		uart4 = "/soc@0/bus@30800000/serial@30a60000";
		mu = "/soc@0/bus@30800000/mailbox@30aa0000";
		i2c5 = "/soc@0/bus@30800000/i2c@30ad0000";
		i2c6 = "/soc@0/bus@30800000/i2c@30ae0000";
		usdhc1 = "/soc@0/bus@30800000/mmc@30b40000";
		usdhc2 = "/soc@0/bus@30800000/mmc@30b50000";
		usdhc3 = "/soc@0/bus@30800000/mmc@30b60000";
		flexspi = "/soc@0/bus@30800000/spi@30bb0000";
		sdma1 = "/soc@0/bus@30800000/dma-controller@30bd0000";
		fec = "/soc@0/bus@30800000/ethernet@30be0000";
		ethphy1 = "/soc@0/bus@30800000/ethernet@30be0000/mdio/ethernet-phy@7";
		eqos = "/soc@0/bus@30800000/ethernet@30bf0000";
		ethphy0 = "/soc@0/bus@30800000/ethernet@30bf0000/mdio/ethernet-phy@7";
		mtl_rx_setup = "/soc@0/bus@30800000/ethernet@30bf0000/rx-queues-config";
		mtl_tx_setup = "/soc@0/bus@30800000/ethernet@30bf0000/tx-queues-config";
		aips4 = "/soc@0/bus@32c00000";
		mipi_dsi = "/soc@0/bus@32c00000/mipi_dsi@32e60000";
		dsim_from_lcdif = "/soc@0/bus@32c00000/mipi_dsi@32e60000/port@0/endpoint";
		lcdif1 = "/soc@0/bus@32c00000/lcd-controller@32e80000";
		lcdif1_disp = "/soc@0/bus@32c00000/lcd-controller@32e80000/port@0";
		lcdif_to_dsim = "/soc@0/bus@32c00000/lcd-controller@32e80000/port@0/endpoint";
		lcdif2 = "/soc@0/bus@32c00000/lcd-controller@32e90000";
		lcdif2_disp = "/soc@0/bus@32c00000/lcd-controller@32e90000/port@0";
		lcdif2_disp_ldb_ch0 = "/soc@0/bus@32c00000/lcd-controller@32e90000/port@0/endpoint@0";
		lcdif2_disp_ldb_ch1 = "/soc@0/bus@32c00000/lcd-controller@32e90000/port@0/endpoint@1";
		media_blk_ctrl = "/soc@0/bus@32c00000/media-blk-ctrl@32ec0000";
		ldb = "/soc@0/bus@32c00000/ldb@32ec005c";
		lvds_channel0 = "/soc@0/bus@32c00000/ldb@32ec005c/lvds-channel@0";
		ldb_ch0 = "/soc@0/bus@32c00000/ldb@32ec005c/lvds-channel@0/port@0/endpoint";
		lvds_out = "/soc@0/bus@32c00000/ldb@32ec005c/lvds-channel@0/port@1/endpoint";
		ldb_ch1 = "/soc@0/bus@32c00000/ldb@32ec005c/lvds-channel@1/port@0/endpoint";
		ldb_phy = "/soc@0/bus@32c00000/phy@32ec0128";
		ldb_phy1 = "/soc@0/bus@32c00000/phy@32ec0128/port@0";
		ldb_phy2 = "/soc@0/bus@32c00000/phy@32ec0128/port@1";
		mediamix_gpr = "/soc@0/bus@32c00000/media_gpr@32ec0008";
		mediamix_gasket0 = "/soc@0/bus@32c00000/gasket@32ec0060";
		mediamix_gasket1 = "/soc@0/bus@32c00000/gasket@32ec0090";
		isi_chain_buf = "/soc@0/bus@32c00000/isi_chain@32e02000";
		cameradev = "/soc@0/bus@32c00000/camera";
		isi_0 = "/soc@0/bus@32c00000/camera/isi@32e00000";
		isi_1 = "/soc@0/bus@32c00000/camera/isi@32e02000";
		dewarp = "/soc@0/bus@32c00000/camera/dwe@32e30000";
		isp_0 = "/soc@0/bus@32c00000/camera/isp@32e10000";
		isp_1 = "/soc@0/bus@32c00000/camera/isp@32e20000";
		mipi_csi_0 = "/soc@0/bus@32c00000/camera/csi@32e40000";
		mipi_csi_1 = "/soc@0/bus@32c00000/camera/csi@32e50000";
		pcie_phy = "/soc@0/bus@32c00000/pcie-phy@32f00000";
		hsio_mix = "/soc@0/bus@32c00000/hsio-mix@32f10000";
		aips5 = "/soc@0/bus@30c00000";
		sai1 = "/soc@0/bus@30c00000/spba-bus@30c00000/sai@30c10000";
		sai2 = "/soc@0/bus@30c00000/spba-bus@30c00000/sai@30c20000";
		sai3 = "/soc@0/bus@30c00000/spba-bus@30c00000/sai@30c30000";
		sai5 = "/soc@0/bus@30c00000/spba-bus@30c00000/sai@30c50000";
		sai6 = "/soc@0/bus@30c00000/spba-bus@30c00000/sai@30c60000";
		sai7 = "/soc@0/bus@30c00000/spba-bus@30c00000/sai@30c80000";
		easrc = "/soc@0/bus@30c00000/spba-bus@30c00000/easrc@30c90000";
		micfil = "/soc@0/bus@30c00000/spba-bus@30c00000/micfil@30ca0000";
		aud2htx = "/soc@0/bus@30c00000/spba-bus@30c00000/aud2htx@30cb0000";
		xcvr = "/soc@0/bus@30c00000/spba-bus@30c00000/xcvr@30cc0000";
		sdma3 = "/soc@0/bus@30c00000/dma-controller@30e00000";
		sdma2 = "/soc@0/bus@30c00000/dma-controller@30e10000";
		audio_blk_ctrl = "/soc@0/bus@30c00000/audio-blk-ctrl@30e20000";
		audiomix_dsp = "/soc@0/bus@30c00000/audiomix_dsp";
		mu2 = "/soc@0/bus@30c00000/mu2@30e60000";
		hdmi_blk_ctrl = "/soc@0/bus@30c00000/hdmi-blk-ctrl@32fc0000";
		irqsteer_hdmi = "/soc@0/bus@30c00000/irqsteer@32fc2000";
		hdmi_pavi = "/soc@0/bus@30c00000/hdmi-pai-pvi@32fc4000";
		lcdif3 = "/soc@0/bus@30c00000/lcd-controller@32fc6000";
		lcdif3_disp = "/soc@0/bus@30c00000/lcd-controller@32fc6000/port@0";
		lcdif3_to_hdmi = "/soc@0/bus@30c00000/lcd-controller@32fc6000/port@0/endpoint";
		hdmi = "/soc@0/bus@30c00000/hdmi@32fd8000";
		hdmi_from_lcdif3 = "/soc@0/bus@30c00000/hdmi@32fd8000/port@0/endpoint";
		hdmiphy = "/soc@0/bus@30c00000/hdmiphy@32fdff00";
		gic = "/soc@0/interrupt-controller@38800000";
		dma_apbh = "/soc@0/dma-apbh@33000000";
		gpmi = "/soc@0/gpmi-nand@33002000";
		pcie = "/soc@0/pcie@33800000";
		pcie_ep = "/soc@0/pcie_ep@33800000";
		usb3_phy0 = "/soc@0/usb-phy@381f0040";
		usb3_0 = "/soc@0/usb@32f10100";
		usb_dwc3_0 = "/soc@0/usb@32f10100/usb@38100000";
		usb3_phy1 = "/soc@0/usb-phy@382f0040";
		usb3_1 = "/soc@0/usb@32f10108";
		usb_dwc3_1 = "/soc@0/usb@32f10108/usb@38200000";
		usb_hub_3_0 = "/soc@0/usb@32f10108/usb@38200000/usb-hub@1";
		usb_hub_2_0 = "/soc@0/usb@32f10108/usb@38200000/usb-hub@2";
		edacmc = "/soc@0/memory-controller@3d400000";
		vpu_g1 = "/vpu_g1@38300000";
		vpu_g2 = "/vpu_g2@38310000";
		vpu_vc8000e = "/vpu_vc8000e@38320000";
		vpu_v4l2 = "/vpu_v4l2";
		gpu_3d = "/gpu3d@38000000";
		gpu_2d = "/gpu2d@38008000";
		ml_vipsi = "/vipsi@38500000";
		mix_gpu_ml = "/mix_gpu_ml";
		i2c_rpbus_3 = "/i2c-rpbus-3";
		etm0 = "/etm@28440000";
		etm0_out_port = "/etm@28440000/out-ports/port/endpoint";
		etm1 = "/etm@28540000";
		etm1_out_port = "/etm@28540000/out-ports/port/endpoint";
		etm2 = "/etm@28640000";
		etm2_out_port = "/etm@28640000/out-ports/port/endpoint";
		etm3 = "/etm@28740000";
		etm3_out_port = "/etm@28740000/out-ports/port/endpoint";
		funnel0 = "/funnel";
		ca_funnel_in_port0 = "/funnel/in-ports/port@0/endpoint";
		ca_funnel_in_port1 = "/funnel/in-ports/port@1/endpoint";
		ca_funnel_in_port2 = "/funnel/in-ports/port@2/endpoint";
		ca_funnel_in_port3 = "/funnel/in-ports/port@3/endpoint";
		ca_funnel_out_port0 = "/funnel/out-ports/port/endpoint";
		funnel1 = "/funnel@28c03000";
		hugo_funnel_in_port0 = "/funnel@28c03000/in-ports/port@0/endpoint";
		hugo_funnel_in_port1 = "/funnel@28c03000/in-ports/port@1/endpoint";
		hugo_funnel_in_port2 = "/funnel@28c03000/in-ports/port@2/endpoint";
		hugo_funnel_out_port0 = "/funnel@28c03000/out-ports/port/endpoint";
		etf_in_port = "/etf@28c04000/in-ports/port/endpoint";
		etf_out_port = "/etf@28c04000/out-ports/port/endpoint";
		etr_in_port = "/etr@28c06000/in-ports/port/endpoint";
		backlight = "/backlight";
		backlight_mezzanine = "/backlight-mezzanine";
		hdmi_connector = "/hdmi-connector";
		panel_lvds = "/panel-lvds";
		panel_lvds_mez = "/panel-lvds-mez";
		panel_lvds_in = "/panel-lvds-mez/port/endpoint";
		sound_hdmi = "/sound-hdmi";
		reg_1p8v = "/regulator-1p8v";
		reg_3p3v = "/regulator-3p3v";
		reg_5p0v = "/regulator-5p0v";
		reg_module_eth1phy = "/regulator-module-eth1phy";
		reg_force_sleep_moci = "/regulator-force-sleep-moci";
		reg_usb1_vbus = "/regulator-usb1-vbus";
		reg_usb2_vbus = "/regulator-usb2-vbus";
		reg_usdhc2_vmmc = "/regulator-usdhc2";
		codec_dai = "/sound/simple-audio-card,codec";
		reg_usb_hub = "/regulator-usb-hub";
		reg_pcie = "/regulator-pcie";
	};
};
